VERSION ""

NS_ :

BS_:

BU_:

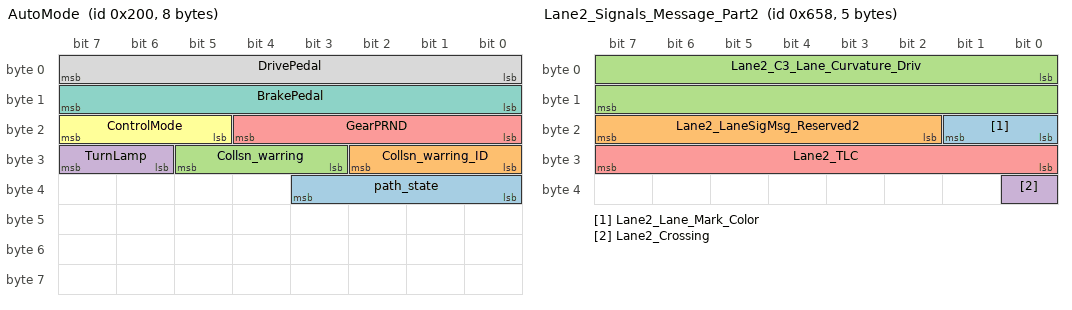
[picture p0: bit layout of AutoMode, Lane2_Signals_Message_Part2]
BO_ 512 AutoMode: 8 Vector__XXX
 SG_ path_state : 35|4@0+ (1,0) [0|15] "" Vector__XXX
 SG_ Collsn_warring_ID : 26|3@0+ (1,0) [0|5] "" Vector__XXX
 SG_ Collsn_warring : 29|3@0+ (1,0) [0|3] "" Vector__XXX
 SG_ TurnLamp : 31|2@0+ (1,0) [0|3] "" Vector__XXX
 SG_ GearPRND : 20|5@0- (1,0) [-9|1] "" Vector__XXX
 SG_ ControlMode : 23|3@0+ (1,0) [0|2] "" Vector__XXX
 SG_ BrakePedal : 15|8@0+ (0.5,0) [0|100] "" Vector__XXX
 SG_ DrivePedal : 7|8@0+ (0.5,0) [0|100] "" Vector__XXX

BO_ 1624 Lane2_Signals_Message_Part2: 5 Vector__XXX
 SG_ Lane2_Lane_Mark_Color : 16|2@1+ (1,0) [0|3] "ENUM" Vector__XXX
 SG_ Lane2_LaneSigMsg_Reserved2 : 18|6@1+ (1,0) [0|0] "NA" Vector__XXX
 SG_ Lane2_C3_Lane_Curvature_Driv : 0|16@1+ (4E-009,-0.000131072) [-0.000131072|0.000131068] "1/m2" Vector__XXX
 SG_ Lane2_Crossing : 32|1@1+ (1,0) [0|1] "bool" Vector__XXX
 SG_ Lane2_TLC : 24|8@1+ (0.01,0) [0|2] "sec" Vector__XXX

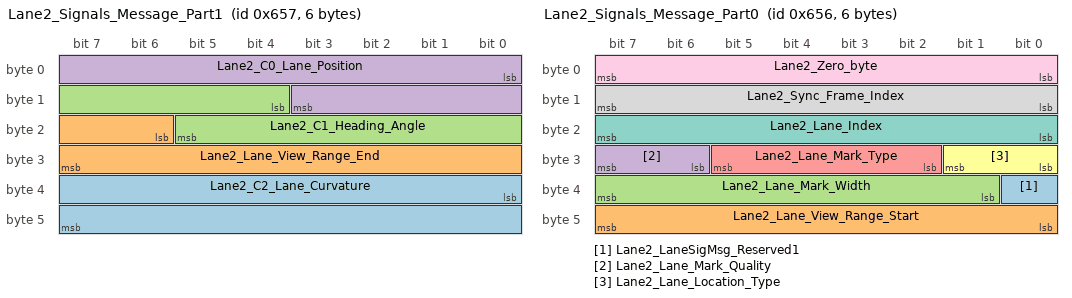
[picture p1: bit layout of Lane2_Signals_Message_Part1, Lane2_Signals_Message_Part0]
BO_ 1623 Lane2_Signals_Message_Part1: 6 Vector__XXX
 SG_ Lane2_C2_Lane_Curvature : 32|16@1+ (1E-006,-0.032768) [-0.032768|0.032767] "1/m" Vector__XXX
 SG_ Lane2_Lane_View_Range_End : 22|10@1+ (0.5,0) [0|150] "m" Vector__XXX
 SG_ Lane2_C1_Heading_Angle : 12|10@1+ (0.0009765625,-0.357) [-0.357|0.357] "rad" Vector__XXX
 SG_ Lane2_C0_Lane_Position : 0|12@1+ (0.01,-20.48) [-20.48|20.47] "m" Vector__XXX

BO_ 1622 Lane2_Signals_Message_Part0: 6 Vector__XXX
 SG_ Lane2_LaneSigMsg_Reserved1 : 32|1@1+ (1,0) [0|0] "NA" Vector__XXX
 SG_ Lane2_Lane_View_Range_Start : 40|8@1+ (0.5,0) [0|63.5] "m" Vector__XXX
 SG_ Lane2_Lane_Mark_Width : 33|7@1+ (0.01,0) [0|0.8] "m" Vector__XXX
 SG_ Lane2_Lane_Mark_Quality : 30|2@1+ (1,0) [0|3] "ENUM" Vector__XXX
 SG_ Lane2_Lane_Mark_Type : 26|4@1+ (1,0) [0|6] "ENUM" Vector__XXX
 SG_ Lane2_Lane_Location_Type : 24|2@1+ (1,0) [0|3] "ENUM" Vector__XXX
 SG_ Lane2_Lane_Index : 16|8@1+ (1,0) [0|3] "counter" Vector__XXX
 SG_ Lane2_Sync_Frame_Index : 8|8@1+ (1,0) [0|255] "counter" Vector__XXX
 SG_ Lane2_Zero_byte : 0|8@1+ (1,0) [0|0] "NA" Vector__XXX

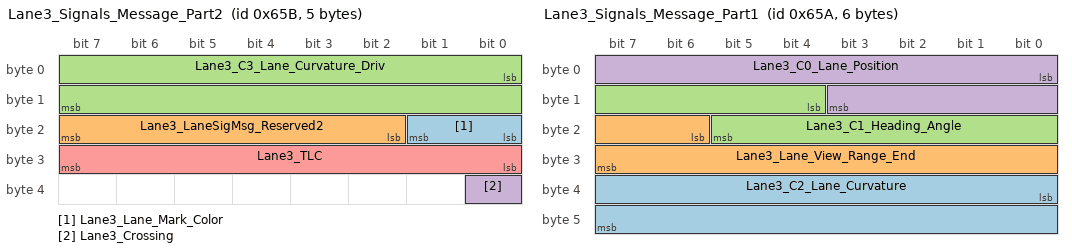
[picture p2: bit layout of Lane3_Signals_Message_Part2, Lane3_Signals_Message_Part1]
BO_ 1627 Lane3_Signals_Message_Part2: 5 Vector__XXX
 SG_ Lane3_Lane_Mark_Color : 16|2@1+ (1,0) [0|3] "ENUM" Vector__XXX
 SG_ Lane3_LaneSigMsg_Reserved2 : 18|6@1+ (1,0) [0|0] "NA" Vector__XXX
 SG_ Lane3_C3_Lane_Curvature_Driv : 0|16@1+ (4E-009,-0.000131072) [-0.000131072|0.000131068] "1/m2" Vector__XXX
 SG_ Lane3_Crossing : 32|1@1+ (1,0) [0|1] "bool" Vector__XXX
 SG_ Lane3_TLC : 24|8@1+ (0.01,0) [0|2] "sec" Vector__XXX

BO_ 1626 Lane3_Signals_Message_Part1: 6 Vector__XXX
 SG_ Lane3_C2_Lane_Curvature : 32|16@1+ (1E-006,-0.032768) [-0.032768|0.032767] "1/m" Vector__XXX
 SG_ Lane3_Lane_View_Range_End : 22|10@1+ (0.5,0) [0|150] "m" Vector__XXX
 SG_ Lane3_C1_Heading_Angle : 12|10@1+ (0.0009765625,-0.357) [-0.357|0.357] "rad" Vector__XXX
 SG_ Lane3_C0_Lane_Position : 0|12@1+ (0.01,-20.48) [-20.48|20.47] "m" Vector__XXX

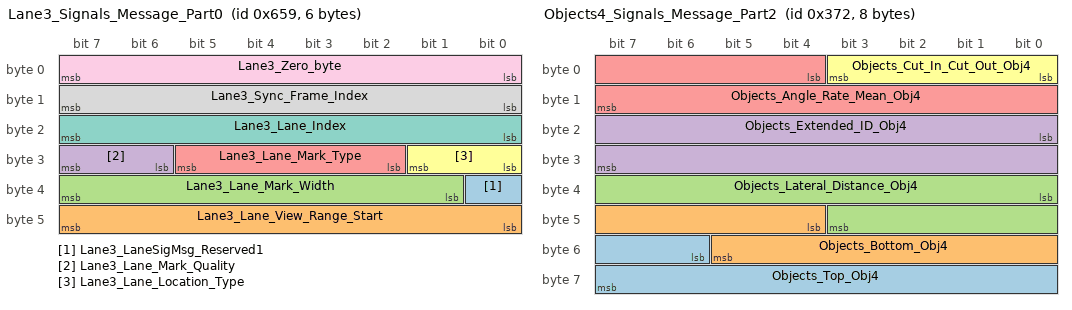
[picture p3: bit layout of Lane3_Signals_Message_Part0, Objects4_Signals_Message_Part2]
BO_ 1625 Lane3_Signals_Message_Part0: 6 Vector__XXX
 SG_ Lane3_LaneSigMsg_Reserved1 : 32|1@1+ (1,0) [0|0] "NA" Vector__XXX
 SG_ Lane3_Lane_View_Range_Start : 40|8@1+ (0.5,0) [0|63.5] "m" Vector__XXX
 SG_ Lane3_Lane_Mark_Width : 33|7@1+ (0.01,0) [0|0.8] "m" Vector__XXX
 SG_ Lane3_Lane_Mark_Quality : 30|2@1+ (1,0) [0|3] "ENUM" Vector__XXX
 SG_ Lane3_Lane_Mark_Type : 26|4@1+ (1,0) [0|6] "ENUM" Vector__XXX
 SG_ Lane3_Lane_Location_Type : 24|2@1+ (1,0) [0|3] "ENUM" Vector__XXX
 SG_ Lane3_Lane_Index : 16|8@1+ (1,0) [0|3] "counter" Vector__XXX
 SG_ Lane3_Sync_Frame_Index : 8|8@1+ (1,0) [0|255] "counter" Vector__XXX
 SG_ Lane3_Zero_byte : 0|8@1+ (1,0) [0|0] "NA" Vector__XXX

BO_ 882 Objects4_Signals_Message_Part2: 8 Vector__XXX
 SG_ Objects_Top_Obj4 : 54|10@1+ (2,-1023) [-1023|1023] "pixels" Vector__XXX
 SG_ Objects_Bottom_Obj4 : 44|10@1+ (2,-1023) [-1023|1023] "pixels" Vector__XXX
 SG_ Objects_Lateral_Distance_Obj4 : 32|12@1+ (0.05,-102.4) [-102.4|102.35] "m" Vector__XXX
 SG_ Objects_Extended_ID_Obj4 : 16|16@1+ (1,0) [0|65535] "counter" Vector__XXX
 SG_ Objects_Angle_Rate_Mean_Obj4 : 4|12@1+ (0.002,-2.234) [-2.234|2.2318] "rad/s" Vector__XXX
 SG_ Objects_Cut_In_Cut_Out_Obj4 : 0|4@1+ (1,0) [0|8] "ENUM" Vector__XXX

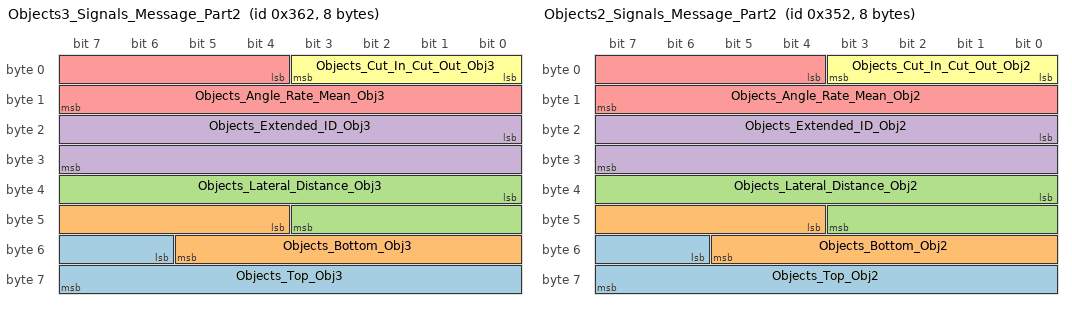
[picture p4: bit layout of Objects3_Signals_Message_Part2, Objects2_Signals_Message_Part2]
BO_ 866 Objects3_Signals_Message_Part2: 8 Vector__XXX
 SG_ Objects_Top_Obj3 : 54|10@1+ (2,-1023) [-1023|1023] "pixels" Vector__XXX
 SG_ Objects_Bottom_Obj3 : 44|10@1+ (2,-1023) [-1023|1023] "pixels" Vector__XXX
 SG_ Objects_Lateral_Distance_Obj3 : 32|12@1+ (0.05,-102.4) [-102.4|102.35] "m" Vector__XXX
 SG_ Objects_Extended_ID_Obj3 : 16|16@1+ (1,0) [0|65535] "counter" Vector__XXX
 SG_ Objects_Angle_Rate_Mean_Obj3 : 4|12@1+ (0.002,-2.234) [-2.234|2.2318] "rad/s" Vector__XXX
 SG_ Objects_Cut_In_Cut_Out_Obj3 : 0|4@1+ (1,0) [0|8] "ENUM" Vector__XXX

BO_ 850 Objects2_Signals_Message_Part2: 8 Vector__XXX
 SG_ Objects_Top_Obj2 : 54|10@1+ (2,-1023) [-1023|1023] "pixels" Vector__XXX
 SG_ Objects_Bottom_Obj2 : 44|10@1+ (2,-1023) [-1023|1023] "pixels" Vector__XXX
 SG_ Objects_Lateral_Distance_Obj2 : 32|12@1+ (0.05,-102.4) [-102.4|102.35] "m" Vector__XXX
 SG_ Objects_Extended_ID_Obj2 : 16|16@1+ (1,0) [0|65535] "counter" Vector__XXX
 SG_ Objects_Angle_Rate_Mean_Obj2 : 4|12@1+ (0.002,-2.234) [-2.234|2.2318] "rad/s" Vector__XXX
 SG_ Objects_Cut_In_Cut_Out_Obj2 : 0|4@1+ (1,0) [0|8] "ENUM" Vector__XXX

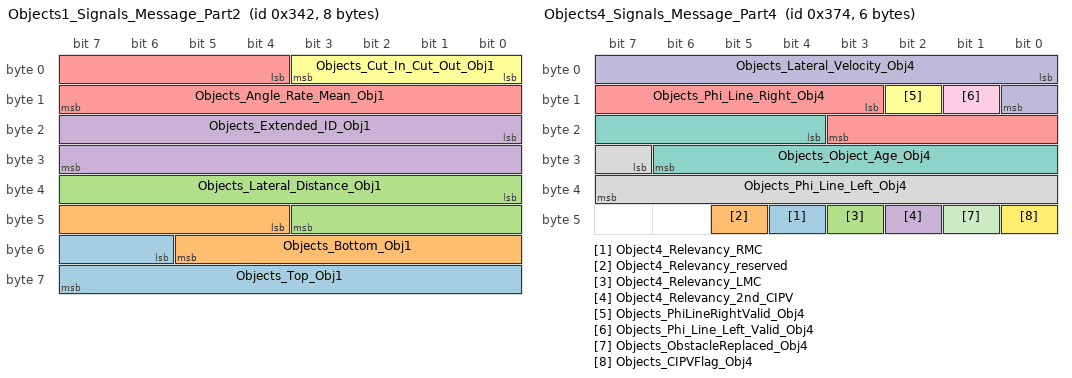
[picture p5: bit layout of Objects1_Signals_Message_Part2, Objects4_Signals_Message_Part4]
BO_ 834 Objects1_Signals_Message_Part2: 8 Vector__XXX
 SG_ Objects_Top_Obj1 : 54|10@1+ (2,-1023) [-1023|1023] "pixels" Vector__XXX
 SG_ Objects_Bottom_Obj1 : 44|10@1+ (2,-1023) [-1023|1023] "pixels" Vector__XXX
 SG_ Objects_Lateral_Distance_Obj1 : 32|12@1+ (0.05,-102.4) [-102.4|102.35] "m" Vector__XXX
 SG_ Objects_Extended_ID_Obj1 : 16|16@1+ (1,0) [0|65535] "counter" Vector__XXX
 SG_ Objects_Angle_Rate_Mean_Obj1 : 4|12@1+ (0.002,-2.234) [-2.234|2.2318] "rad/s" Vector__XXX
 SG_ Objects_Cut_In_Cut_Out_Obj1 : 0|4@1+ (1,0) [0|8] "ENUM" Vector__XXX

BO_ 884 Objects4_Signals_Message_Part4: 6 Vector__XXX
 SG_ Object4_Relevancy_RMC : 44|1@1+ (1,0) [0|0] "boot" Vector__XXX
 SG_ Object4_Relevancy_reserved : 45|1@1+ (1,0) [0|0] "bool" Vector__XXX
 SG_ Object4_Relevancy_LMC : 43|1@1+ (1,0) [0|0] "bool" Vector__XXX
 SG_ Object4_Relevancy_2nd_CIPV : 42|1@1+ (1,0) [0|0] "bool" Vector__XXX
 SG_ Objects_Phi_Line_Right_Obj4 : 11|9@1+ (0.0010246551382,-0.2617993878) [-0.2617993878|0.2617993878] "rad" Vector__XXX
 SG_ Objects_PhiLineRightValid_Obj4 : 10|1@1+ (1,0) [0|1] "bool" Vector__XXX
 SG_ Objects_Object_Age_Obj4 : 20|11@1+ (1,0) [0|2047] "frames" Vector__XXX
 SG_ Objects_Phi_Line_Left_Obj4 : 31|9@1+ (0.0010246551382,-0.2617993878) [-0.2617993878|0.2617993878] "rad" Vector__XXX
 SG_ Objects_Phi_Line_Left_Valid_Obj4 : 9|1@1+ (1,0) [0|1] "bool" Vector__XXX
 SG_ Objects_Lateral_Velocity_Obj4 : 0|9@1+ (0.05,-12.8) [-12.8|12.75] "m/s" Vector__XXX
 SG_ Objects_ObstacleReplaced_Obj4 : 41|1@1+ (1,0) [0|1] "bool" Vector__XXX
 SG_ Objects_CIPVFlag_Obj4 : 40|1@1+ (1,0) [0|1] "bool" Vector__XXX

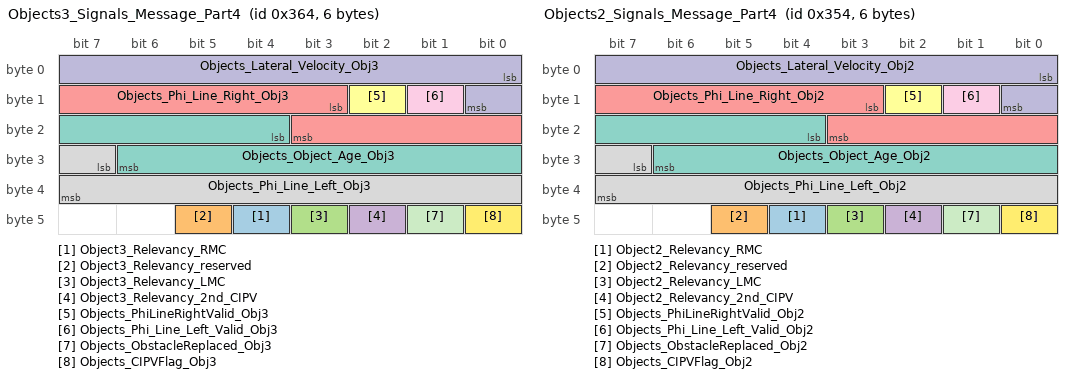
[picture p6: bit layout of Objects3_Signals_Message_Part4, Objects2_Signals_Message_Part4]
BO_ 868 Objects3_Signals_Message_Part4: 6 Vector__XXX
 SG_ Object3_Relevancy_RMC : 44|1@1+ (1,0) [0|0] "boot" Vector__XXX
 SG_ Object3_Relevancy_reserved : 45|1@1+ (1,0) [0|0] "bool" Vector__XXX
 SG_ Object3_Relevancy_LMC : 43|1@1+ (1,0) [0|0] "bool" Vector__XXX
 SG_ Object3_Relevancy_2nd_CIPV : 42|1@1+ (1,0) [0|0] "bool" Vector__XXX
 SG_ Objects_Phi_Line_Right_Obj3 : 11|9@1+ (0.0010246551382,-0.2617993878) [-0.2617993878|0.2617993878] "rad" Vector__XXX
 SG_ Objects_PhiLineRightValid_Obj3 : 10|1@1+ (1,0) [0|1] "bool" Vector__XXX
 SG_ Objects_Object_Age_Obj3 : 20|11@1+ (1,0) [0|2047] "frames" Vector__XXX
 SG_ Objects_Phi_Line_Left_Obj3 : 31|9@1+ (0.0010246551382,-0.2617993878) [-0.2617993878|0.2617993878] "rad" Vector__XXX
 SG_ Objects_Phi_Line_Left_Valid_Obj3 : 9|1@1+ (1,0) [0|1] "bool" Vector__XXX
 SG_ Objects_Lateral_Velocity_Obj3 : 0|9@1+ (0.05,-12.8) [-12.8|12.75] "m/s" Vector__XXX
 SG_ Objects_ObstacleReplaced_Obj3 : 41|1@1+ (1,0) [0|1] "bool" Vector__XXX
 SG_ Objects_CIPVFlag_Obj3 : 40|1@1+ (1,0) [0|1] "bool" Vector__XXX

BO_ 852 Objects2_Signals_Message_Part4: 6 Vector__XXX
 SG_ Object2_Relevancy_RMC : 44|1@1+ (1,0) [0|0] "boot" Vector__XXX
 SG_ Object2_Relevancy_reserved : 45|1@1+ (1,0) [0|0] "bool" Vector__XXX
 SG_ Object2_Relevancy_LMC : 43|1@1+ (1,0) [0|0] "bool" Vector__XXX
 SG_ Object2_Relevancy_2nd_CIPV : 42|1@1+ (1,0) [0|0] "bool" Vector__XXX
 SG_ Objects_Phi_Line_Right_Obj2 : 11|9@1+ (0.0010246551382,-0.2617993878) [-0.2617993878|0.2617993878] "rad" Vector__XXX
 SG_ Objects_PhiLineRightValid_Obj2 : 10|1@1+ (1,0) [0|1] "bool" Vector__XXX
 SG_ Objects_Object_Age_Obj2 : 20|11@1+ (1,0) [0|2047] "frames" Vector__XXX
 SG_ Objects_Phi_Line_Left_Obj2 : 31|9@1+ (0.0010246551382,-0.2617993878) [-0.2617993878|0.2617993878] "rad" Vector__XXX
 SG_ Objects_Phi_Line_Left_Valid_Obj2 : 9|1@1+ (1,0) [0|1] "bool" Vector__XXX
 SG_ Objects_Lateral_Velocity_Obj2 : 0|9@1+ (0.05,-12.8) [-12.8|12.75] "m/s" Vector__XXX
 SG_ Objects_ObstacleReplaced_Obj2 : 41|1@1+ (1,0) [0|1] "bool" Vector__XXX
 SG_ Objects_CIPVFlag_Obj2 : 40|1@1+ (1,0) [0|1] "bool" Vector__XXX

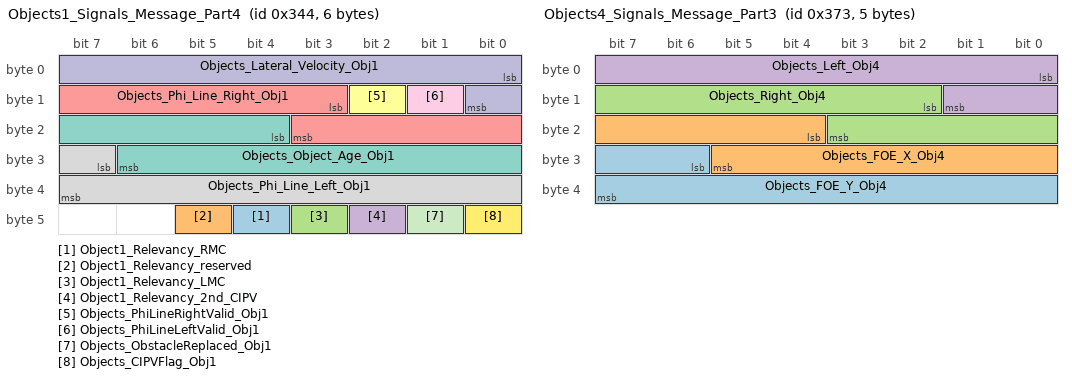
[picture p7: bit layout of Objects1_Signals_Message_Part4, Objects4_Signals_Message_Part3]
BO_ 836 Objects1_Signals_Message_Part4: 6 Vector__XXX
 SG_ Object1_Relevancy_RMC : 44|1@1+ (1,0) [0|0] "boot" Vector__XXX
 SG_ Object1_Relevancy_reserved : 45|1@1+ (1,0) [0|0] "bool" Vector__XXX
 SG_ Object1_Relevancy_LMC : 43|1@1+ (1,0) [0|0] "bool" Vector__XXX
 SG_ Object1_Relevancy_2nd_CIPV : 42|1@1+ (1,0) [0|0] "bool" Vector__XXX
 SG_ Objects_Phi_Line_Right_Obj1 : 11|9@1+ (0.0010246551382,-0.2617993878) [-0.2617993878|0.2617993878] "rad" Vector__XXX
 SG_ Objects_PhiLineRightValid_Obj1 : 10|1@1+ (1,0) [0|1] "bool" Vector__XXX
 SG_ Objects_Object_Age_Obj1 : 20|11@1+ (1,0) [0|2047] "frames" Vector__XXX
 SG_ Objects_Phi_Line_Left_Obj1 : 31|9@1+ (0.0010246551382,-0.2617993878) [-0.2617993878|0.2617993878] "rad" Vector__XXX
 SG_ Objects_PhiLineLeftValid_Obj1 : 9|1@1+ (1,0) [0|1] "bool" Vector__XXX
 SG_ Objects_Lateral_Velocity_Obj1 : 0|9@1+ (0.05,-12.8) [-12.8|12.75] "m/s" Vector__XXX
 SG_ Objects_ObstacleReplaced_Obj1 : 41|1@1+ (1,0) [0|1] "bool" Vector__XXX
 SG_ Objects_CIPVFlag_Obj1 : 40|1@1+ (1,0) [0|1] "bool" Vector__XXX

BO_ 883 Objects4_Signals_Message_Part3: 5 Vector__XXX
 SG_ Objects_FOE_Y_Obj4 : 30|10@1+ (2,-1023) [-1023|1023] "pixels" Vector__XXX
 SG_ Objects_FOE_X_Obj4 : 20|10@1+ (2,-1023) [-1023|1023] "pixels" Vector__XXX
 SG_ Objects_Right_Obj4 : 10|10@1+ (2,-1023) [-1023|1023] "pixels" Vector__XXX
 SG_ Objects_Left_Obj4 : 0|10@1+ (2,-1023) [-1023|1023] "pixels" Vector__XXX

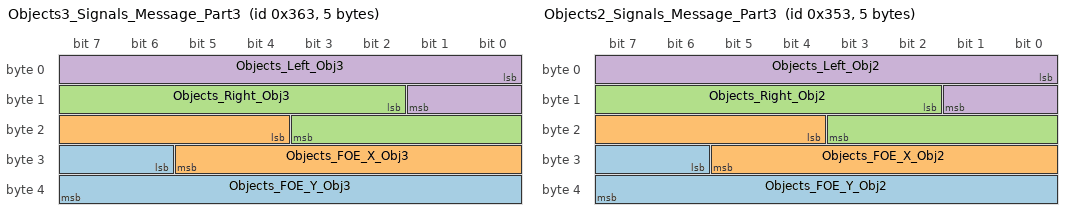
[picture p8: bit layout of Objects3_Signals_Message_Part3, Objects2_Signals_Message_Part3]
BO_ 867 Objects3_Signals_Message_Part3: 5 Vector__XXX
 SG_ Objects_FOE_Y_Obj3 : 30|10@1+ (2,-1023) [-1023|1023] "pixels" Vector__XXX
 SG_ Objects_FOE_X_Obj3 : 20|10@1+ (2,-1023) [-1023|1023] "pixels" Vector__XXX
 SG_ Objects_Right_Obj3 : 10|10@1+ (2,-1023) [-1023|1023] "pixels" Vector__XXX
 SG_ Objects_Left_Obj3 : 0|10@1+ (2,-1023) [-1023|1023] "pixels" Vector__XXX

BO_ 851 Objects2_Signals_Message_Part3: 5 Vector__XXX
 SG_ Objects_FOE_Y_Obj2 : 30|10@1+ (2,-1023) [-1023|1023] "pixels" Vector__XXX
 SG_ Objects_FOE_X_Obj2 : 20|10@1+ (2,-1023) [-1023|1023] "pixels" Vector__XXX
 SG_ Objects_Right_Obj2 : 10|10@1+ (2,-1023) [-1023|1023] "pixels" Vector__XXX
 SG_ Objects_Left_Obj2 : 0|10@1+ (2,-1023) [-1023|1023] "pixels" Vector__XXX

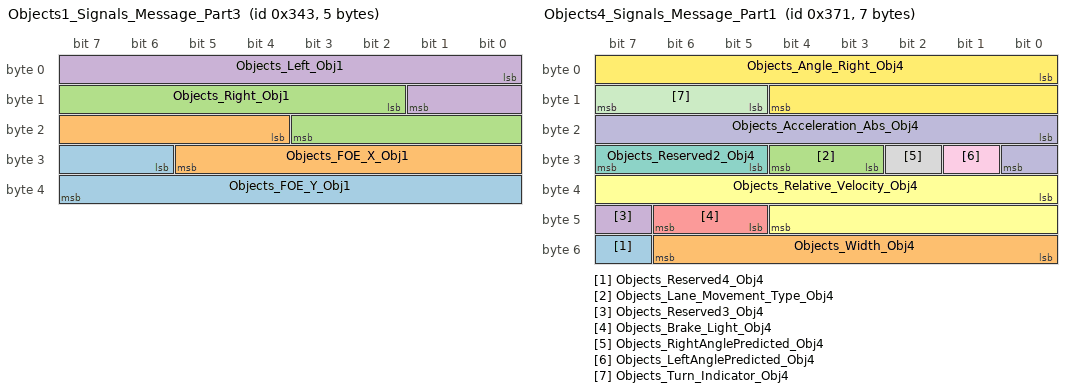
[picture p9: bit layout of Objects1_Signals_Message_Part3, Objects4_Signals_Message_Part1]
BO_ 835 Objects1_Signals_Message_Part3: 5 Vector__XXX
 SG_ Objects_FOE_Y_Obj1 : 30|10@1+ (2,-1023) [-1023|1023] "pixels" Vector__XXX
 SG_ Objects_FOE_X_Obj1 : 20|10@1+ (2,-1023) [-1023|1023] "pixels" Vector__XXX
 SG_ Objects_Right_Obj1 : 10|10@1+ (2,-1023) [-1023|1023] "pixels" Vector__XXX
 SG_ Objects_Left_Obj1 : 0|10@1+ (2,-1023) [-1023|1023] "pixels" Vector__XXX

BO_ 881 Objects4_Signals_Message_Part1: 7 Vector__XXX
 SG_ Objects_Reserved4_Obj4 : 55|1@1+ (1,0) [0|0] "NA" Vector__XXX
 SG_ Objects_Width_Obj4 : 48|7@1+ (0.05,0) [0|6.35] "m" Vector__XXX
 SG_ Objects_Lane_Movement_Type_Obj4 : 27|2@1+ (1,0) [0|2] "ENUM" Vector__XXX
 SG_ Objects_Reserved3_Obj4 : 47|1@1+ (1,0) [0|0] "NA" Vector__XXX
 SG_ Objects_Brake_Light_Obj4 : 45|2@1+ (1,0) [0|2] "ENUM" Vector__XXX
 SG_ Objects_Relative_Velocity_Obj4 : 32|13@1+ (0.05,-128) [-128|128] "m/s" Vector__XXX
 SG_ Objects_Reserved2_Obj4 : 29|3@1+ (1,0) [0|0] "NA" Vector__XXX
 SG_ Objects_RightAnglePredicted_Obj4 : 26|1@1+ (1,0) [0|1] "bool" Vector__XXX
 SG_ Objects_LeftAnglePredicted_Obj4 : 25|1@1+ (1,0) [0|1] "bool" Vector__XXX
 SG_ Objects_Acceleration_Abs_Obj4 : 16|9@1+ (0.05,-12.8) [-12.8|12.75] "m/s2" Vector__XXX
 SG_ Objects_Turn_Indicator_Obj4 : 13|3@1+ (1,0) [0|4] "ENUM" Vector__XXX
 SG_ Objects_Angle_Right_Obj4 : 0|13@1+ (0.0002,-0.8192) [-0.8192|0.819] "rad" Vector__XXX

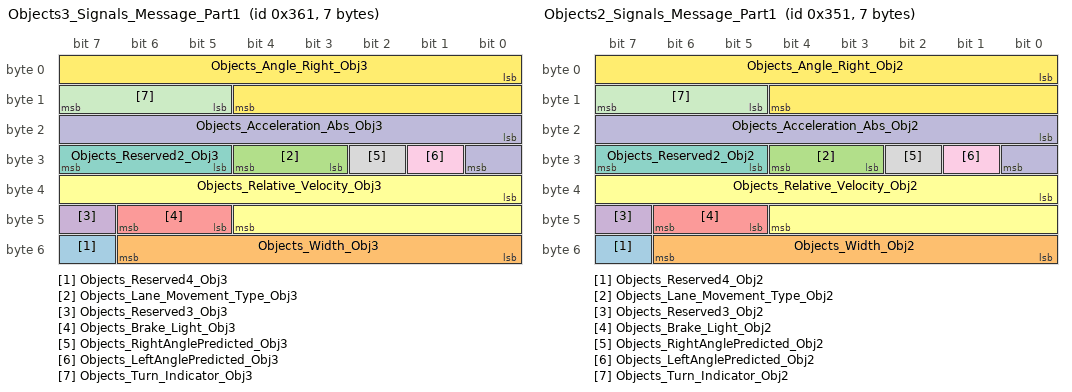
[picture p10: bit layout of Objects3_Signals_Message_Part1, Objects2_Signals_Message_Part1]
BO_ 865 Objects3_Signals_Message_Part1: 7 Vector__XXX
 SG_ Objects_Reserved4_Obj3 : 55|1@1+ (1,0) [0|0] "NA" Vector__XXX
 SG_ Objects_Width_Obj3 : 48|7@1+ (0.05,0) [0|6.35] "m" Vector__XXX
 SG_ Objects_Lane_Movement_Type_Obj3 : 27|2@1+ (1,0) [0|2] "ENUM" Vector__XXX
 SG_ Objects_Reserved3_Obj3 : 47|1@1+ (1,0) [0|0] "NA" Vector__XXX
 SG_ Objects_Brake_Light_Obj3 : 45|2@1+ (1,0) [0|2] "ENUM" Vector__XXX
 SG_ Objects_Relative_Velocity_Obj3 : 32|13@1+ (0.05,-128) [-128|128] "m/s" Vector__XXX
 SG_ Objects_Reserved2_Obj3 : 29|3@1+ (1,0) [0|0] "NA" Vector__XXX
 SG_ Objects_RightAnglePredicted_Obj3 : 26|1@1+ (1,0) [0|1] "bool" Vector__XXX
 SG_ Objects_LeftAnglePredicted_Obj3 : 25|1@1+ (1,0) [0|1] "bool" Vector__XXX
 SG_ Objects_Acceleration_Abs_Obj3 : 16|9@1+ (0.05,-12.8) [-12.8|12.75] "m/s2" Vector__XXX
 SG_ Objects_Turn_Indicator_Obj3 : 13|3@1+ (1,0) [0|4] "ENUM" Vector__XXX
 SG_ Objects_Angle_Right_Obj3 : 0|13@1+ (0.0002,-0.8192) [-0.8192|0.819] "rad" Vector__XXX

BO_ 849 Objects2_Signals_Message_Part1: 7 Vector__XXX
 SG_ Objects_Reserved4_Obj2 : 55|1@1+ (1,0) [0|0] "NA" Vector__XXX
 SG_ Objects_Width_Obj2 : 48|7@1+ (0.05,0) [0|6.35] "m" Vector__XXX
 SG_ Objects_Lane_Movement_Type_Obj2 : 27|2@1+ (1,0) [0|2] "ENUM" Vector__XXX
 SG_ Objects_Reserved3_Obj2 : 47|1@1+ (1,0) [0|0] "NA" Vector__XXX
 SG_ Objects_Brake_Light_Obj2 : 45|2@1+ (1,0) [0|2] "ENUM" Vector__XXX
 SG_ Objects_Relative_Velocity_Obj2 : 32|13@1+ (0.05,-128) [-128|128] "m/s" Vector__XXX
 SG_ Objects_Reserved2_Obj2 : 29|3@1+ (1,0) [0|0] "NA" Vector__XXX
 SG_ Objects_RightAnglePredicted_Obj2 : 26|1@1+ (1,0) [0|1] "bool" Vector__XXX
 SG_ Objects_LeftAnglePredicted_Obj2 : 25|1@1+ (1,0) [0|1] "bool" Vector__XXX
 SG_ Objects_Acceleration_Abs_Obj2 : 16|9@1+ (0.05,-12.8) [-12.8|12.75] "m/s2" Vector__XXX
 SG_ Objects_Turn_Indicator_Obj2 : 13|3@1+ (1,0) [0|4] "ENUM" Vector__XXX
 SG_ Objects_Angle_Right_Obj2 : 0|13@1+ (0.0002,-0.8192) [-0.8192|0.819] "rad" Vector__XXX

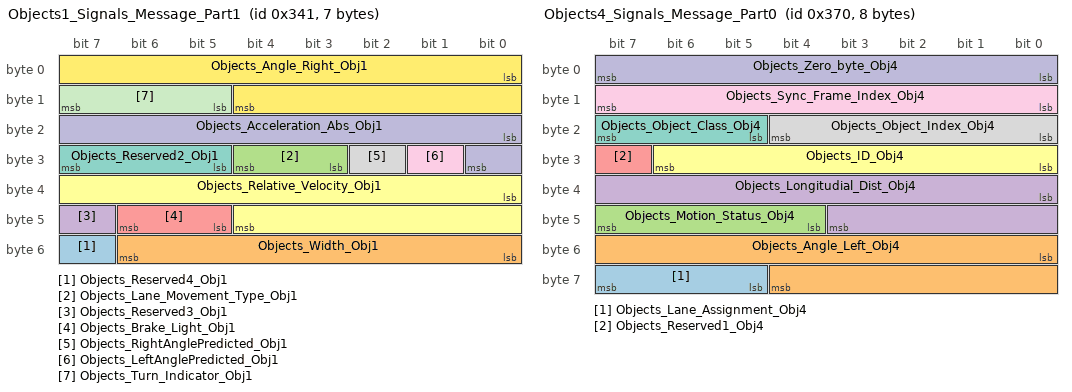
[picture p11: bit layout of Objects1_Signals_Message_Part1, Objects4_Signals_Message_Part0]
BO_ 833 Objects1_Signals_Message_Part1: 7 Vector__XXX
 SG_ Objects_Reserved4_Obj1 : 55|1@1+ (1,0) [0|0] "NA" Vector__XXX
 SG_ Objects_Width_Obj1 : 48|7@1+ (0.05,0) [0|6.35] "m" Vector__XXX
 SG_ Objects_Lane_Movement_Type_Obj1 : 27|2@1+ (1,0) [0|2] "ENUM" Vector__XXX
 SG_ Objects_Reserved3_Obj1 : 47|1@1+ (1,0) [0|0] "NA" Vector__XXX
 SG_ Objects_Brake_Light_Obj1 : 45|2@1+ (1,0) [0|2] "ENUM" Vector__XXX
 SG_ Objects_Relative_Velocity_Obj1 : 32|13@1+ (0.05,-128) [-128|128] "m/s" Vector__XXX
 SG_ Objects_Reserved2_Obj1 : 29|3@1+ (1,0) [0|0] "NA" Vector__XXX
 SG_ Objects_RightAnglePredicted_Obj1 : 26|1@1+ (1,0) [0|1] "bool" Vector__XXX
 SG_ Objects_LeftAnglePredicted_Obj1 : 25|1@1+ (1,0) [0|1] "bool" Vector__XXX
 SG_ Objects_Acceleration_Abs_Obj1 : 16|9@1+ (0.05,-12.8) [-12.8|12.75] "m/s2" Vector__XXX
 SG_ Objects_Turn_Indicator_Obj1 : 13|3@1+ (1,0) [0|4] "ENUM" Vector__XXX
 SG_ Objects_Angle_Right_Obj1 : 0|13@1+ (0.0002,-0.8192) [-0.8192|0.819] "rad" Vector__XXX

BO_ 880 Objects4_Signals_Message_Part0: 8 Vector__XXX
 SG_ Objects_Lane_Assignment_Obj4 : 61|3@1+ (1,0) [0|5] "ENUM" Vector__XXX
 SG_ Objects_Angle_Left_Obj4 : 48|13@1+ (0.0002,-0.8192) [-0.8192|0.819] "rad" Vector__XXX
 SG_ Objects_Motion_Status_Obj4 : 44|4@1+ (1,0) [0|8] "ENUM" Vector__XXX
 SG_ Objects_Longitudial_Dist_Obj4 : 32|12@1+ (0.05,0) [0|204.75] "m" Vector__XXX
 SG_ Objects_Reserved1_Obj4 : 31|1@1+ (1,0) [0|0] "NA" Vector__XXX
 SG_ Objects_ID_Obj4 : 24|7@1+ (1,0) [1|63] "counter" Vector__XXX
 SG_ Objects_Object_Class_Obj4 : 21|3@1+ (1,0) [0|6] "ENUM" Vector__XXX
 SG_ Objects_Object_Index_Obj4 : 16|5@1+ (1,0) [0|19] "counter" Vector__XXX
 SG_ Objects_Sync_Frame_Index_Obj4 : 8|8@1+ (1,0) [0|255] "counter" Vector__XXX
 SG_ Objects_Zero_byte_Obj4 : 0|8@1+ (1,0) [0|0] "NA" Vector__XXX

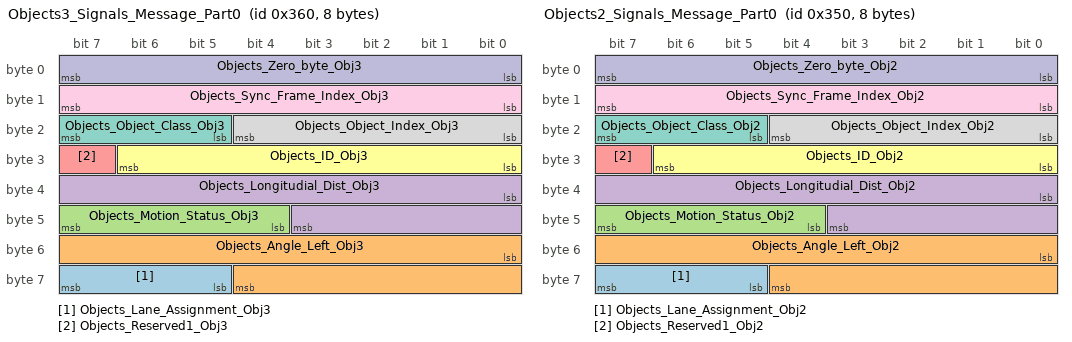
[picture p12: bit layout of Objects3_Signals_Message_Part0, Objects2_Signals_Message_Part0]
BO_ 864 Objects3_Signals_Message_Part0: 8 Vector__XXX
 SG_ Objects_Lane_Assignment_Obj3 : 61|3@1+ (1,0) [0|5] "ENUM" Vector__XXX
 SG_ Objects_Angle_Left_Obj3 : 48|13@1+ (0.0002,-0.8192) [-0.8192|0.819] "rad" Vector__XXX
 SG_ Objects_Motion_Status_Obj3 : 44|4@1+ (1,0) [0|8] "ENUM" Vector__XXX
 SG_ Objects_Longitudial_Dist_Obj3 : 32|12@1+ (0.05,0) [0|204.75] "m" Vector__XXX
 SG_ Objects_Reserved1_Obj3 : 31|1@1+ (1,0) [0|0] "NA" Vector__XXX
 SG_ Objects_ID_Obj3 : 24|7@1+ (1,0) [1|63] "counter" Vector__XXX
 SG_ Objects_Object_Class_Obj3 : 21|3@1+ (1,0) [0|6] "ENUM" Vector__XXX
 SG_ Objects_Object_Index_Obj3 : 16|5@1+ (1,0) [0|19] "counter" Vector__XXX
 SG_ Objects_Sync_Frame_Index_Obj3 : 8|8@1+ (1,0) [0|255] "counter" Vector__XXX
 SG_ Objects_Zero_byte_Obj3 : 0|8@1+ (1,0) [0|0] "NA" Vector__XXX

BO_ 848 Objects2_Signals_Message_Part0: 8 Vector__XXX
 SG_ Objects_Lane_Assignment_Obj2 : 61|3@1+ (1,0) [0|5] "ENUM" Vector__XXX
 SG_ Objects_Angle_Left_Obj2 : 48|13@1+ (0.0002,-0.8192) [-0.8192|0.819] "rad" Vector__XXX
 SG_ Objects_Motion_Status_Obj2 : 44|4@1+ (1,0) [0|8] "ENUM" Vector__XXX
 SG_ Objects_Longitudial_Dist_Obj2 : 32|12@1+ (0.05,0) [0|204.75] "m" Vector__XXX
 SG_ Objects_Reserved1_Obj2 : 31|1@1+ (1,0) [0|0] "NA" Vector__XXX
 SG_ Objects_ID_Obj2 : 24|7@1+ (1,0) [1|63] "counter" Vector__XXX
 SG_ Objects_Object_Class_Obj2 : 21|3@1+ (1,0) [0|6] "ENUM" Vector__XXX
 SG_ Objects_Object_Index_Obj2 : 16|5@1+ (1,0) [0|19] "counter" Vector__XXX
 SG_ Objects_Sync_Frame_Index_Obj2 : 8|8@1+ (1,0) [0|255] "counter" Vector__XXX
 SG_ Objects_Zero_byte_Obj2 : 0|8@1+ (1,0) [0|0] "NA" Vector__XXX

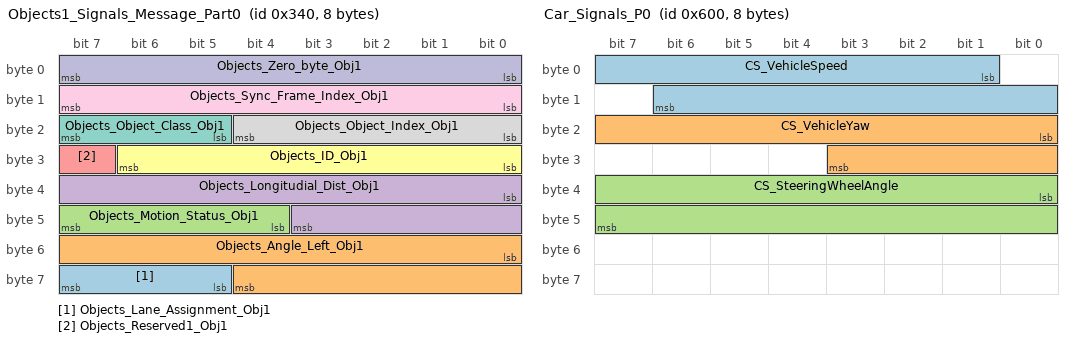
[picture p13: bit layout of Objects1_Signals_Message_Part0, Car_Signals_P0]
BO_ 832 Objects1_Signals_Message_Part0: 8 Vector__XXX
 SG_ Objects_Lane_Assignment_Obj1 : 61|3@1+ (1,0) [0|5] "ENUM" Vector__XXX
 SG_ Objects_Angle_Left_Obj1 : 48|13@1+ (0.0002,-0.8192) [-0.8192|0.819] "rad" Vector__XXX
 SG_ Objects_Motion_Status_Obj1 : 44|4@1+ (1,0) [0|8] "ENUM" Vector__XXX
 SG_ Objects_Longitudial_Dist_Obj1 : 32|12@1+ (0.05,0) [0|204.75] "m" Vector__XXX
 SG_ Objects_Reserved1_Obj1 : 31|1@1+ (1,0) [0|0] "NA" Vector__XXX
 SG_ Objects_ID_Obj1 : 24|7@1+ (1,0) [1|63] "counter" Vector__XXX
 SG_ Objects_Object_Class_Obj1 : 21|3@1+ (1,0) [0|6] "ENUM" Vector__XXX
 SG_ Objects_Object_Index_Obj1 : 16|5@1+ (1,0) [0|19] "counter" Vector__XXX
 SG_ Objects_Sync_Frame_Index_Obj1 : 8|8@1+ (1,0) [0|255] "counter" Vector__XXX
 SG_ Objects_Zero_byte_Obj1 : 0|8@1+ (1,0) [0|0] "NA" Vector__XXX

BO_ 1536 Car_Signals_P0: 8 Vector__XXX
 SG_ CS_VehicleSpeed : 1|14@1+ (0.01,0) [0|163.83] "m/s" Vector__XXX
 SG_ CS_VehicleYaw : 16|12@1+ (0.0625,-128) [-128|127.938] "deg/sec" Vector__XXX
 SG_ CS_SteeringWheelAngle : 32|16@1+ (0.0625,-2048) [-2048|2047.94] "deg" Vector__XXX

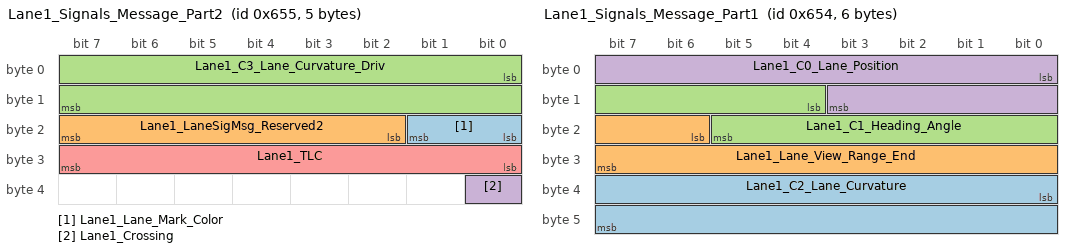
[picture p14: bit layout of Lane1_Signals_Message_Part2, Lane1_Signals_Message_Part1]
BO_ 1621 Lane1_Signals_Message_Part2: 5 Vector__XXX
 SG_ Lane1_Lane_Mark_Color : 16|2@1+ (1,0) [0|3] "ENUM" Vector__XXX
 SG_ Lane1_LaneSigMsg_Reserved2 : 18|6@1+ (1,0) [0|0] "NA" Vector__XXX
 SG_ Lane1_C3_Lane_Curvature_Driv : 0|16@1+ (4E-009,-0.000131072) [-0.000131072|0.000131068] "1/m2" Vector__XXX
 SG_ Lane1_Crossing : 32|1@1+ (1,0) [0|1] "bool" Vector__XXX
 SG_ Lane1_TLC : 24|8@1+ (0.01,0) [0|2] "sec" Vector__XXX

BO_ 1620 Lane1_Signals_Message_Part1: 6 Vector__XXX
 SG_ Lane1_C2_Lane_Curvature : 32|16@1+ (1E-006,-0.032768) [-0.032768|0.032767] "1/m" Vector__XXX
 SG_ Lane1_Lane_View_Range_End : 22|10@1+ (0.5,0) [0|150] "m" Vector__XXX
 SG_ Lane1_C1_Heading_Angle : 12|10@1+ (0.0009765625,-0.357) [-0.357|0.357] "rad" Vector__XXX
 SG_ Lane1_C0_Lane_Position : 0|12@1+ (0.01,-20.48) [-20.48|20.47] "m" Vector__XXX

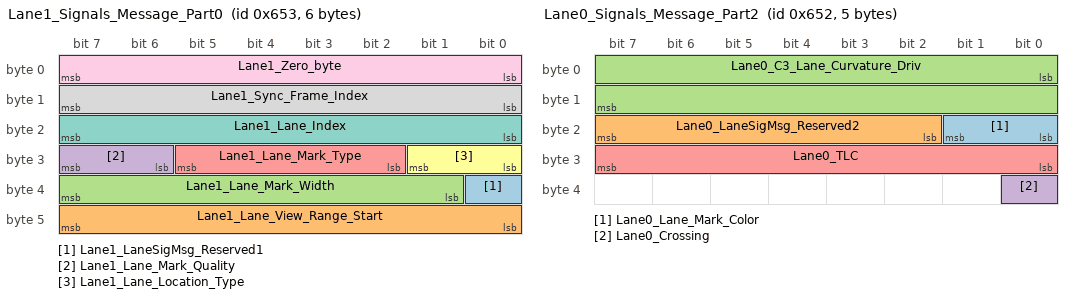
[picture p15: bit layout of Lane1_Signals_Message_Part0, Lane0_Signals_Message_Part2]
BO_ 1619 Lane1_Signals_Message_Part0: 6 Vector__XXX
 SG_ Lane1_LaneSigMsg_Reserved1 : 32|1@1+ (1,0) [0|0] "NA" Vector__XXX
 SG_ Lane1_Lane_View_Range_Start : 40|8@1+ (0.5,0) [0|63.5] "m" Vector__XXX
 SG_ Lane1_Lane_Mark_Width : 33|7@1+ (0.01,0) [0|0.8] "m" Vector__XXX
 SG_ Lane1_Lane_Mark_Quality : 30|2@1+ (1,0) [0|3] "ENUM" Vector__XXX
 SG_ Lane1_Lane_Mark_Type : 26|4@1+ (1,0) [0|6] "ENUM" Vector__XXX
 SG_ Lane1_Lane_Location_Type : 24|2@1+ (1,0) [0|3] "ENUM" Vector__XXX
 SG_ Lane1_Lane_Index : 16|8@1+ (1,0) [0|3] "counter" Vector__XXX
 SG_ Lane1_Sync_Frame_Index : 8|8@1+ (1,0) [0|255] "counter" Vector__XXX
 SG_ Lane1_Zero_byte : 0|8@1+ (1,0) [0|0] "NA" Vector__XXX

BO_ 1618 Lane0_Signals_Message_Part2: 5 Vector__XXX
 SG_ Lane0_Lane_Mark_Color : 16|2@1+ (1,0) [0|3] "ENUM" Vector__XXX
 SG_ Lane0_LaneSigMsg_Reserved2 : 18|6@1+ (1,0) [0|0] "NA" Vector__XXX
 SG_ Lane0_C3_Lane_Curvature_Driv : 0|16@1+ (4E-009,-0.000131072) [-0.000131072|0.000131068] "1/m2" Vector__XXX
 SG_ Lane0_Crossing : 32|1@1+ (1,0) [0|1] "bool" Vector__XXX
 SG_ Lane0_TLC : 24|8@1+ (0.01,0) [0|2] "sec" Vector__XXX

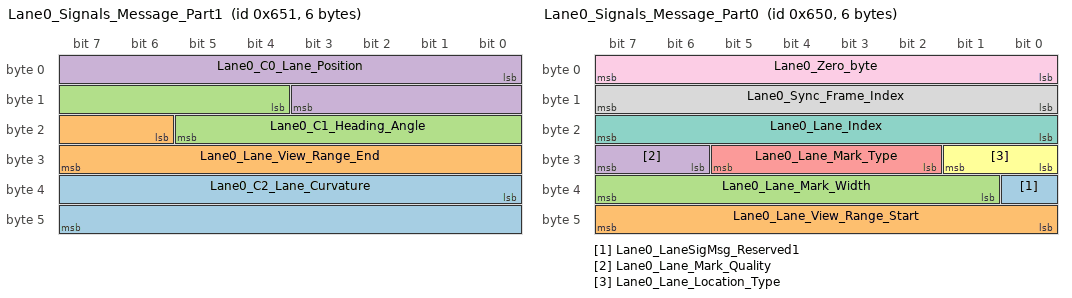
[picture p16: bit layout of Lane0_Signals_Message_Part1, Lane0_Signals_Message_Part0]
BO_ 1617 Lane0_Signals_Message_Part1: 6 Vector__XXX
 SG_ Lane0_C2_Lane_Curvature : 32|16@1+ (1E-006,-0.032768) [-0.032768|0.032767] "1/m" Vector__XXX
 SG_ Lane0_Lane_View_Range_End : 22|10@1+ (0.5,0) [0|150] "m" Vector__XXX
 SG_ Lane0_C1_Heading_Angle : 12|10@1+ (0.0009765625,-0.357) [-0.357|0.357] "rad" Vector__XXX
 SG_ Lane0_C0_Lane_Position : 0|12@1+ (0.01,-20.48) [-20.48|20.47] "m" Vector__XXX

BO_ 1616 Lane0_Signals_Message_Part0: 6 Vector__XXX
 SG_ Lane0_LaneSigMsg_Reserved1 : 32|1@1+ (1,0) [0|0] "NA" Vector__XXX
 SG_ Lane0_Lane_View_Range_Start : 40|8@1+ (0.5,0) [0|63.5] "m" Vector__XXX
 SG_ Lane0_Lane_Mark_Width : 33|7@1+ (0.01,0) [0|0.8] "m" Vector__XXX
 SG_ Lane0_Lane_Mark_Quality : 30|2@1+ (1,0) [0|3] "ENUM" Vector__XXX
 SG_ Lane0_Lane_Mark_Type : 26|4@1+ (1,0) [0|6] "ENUM" Vector__XXX
 SG_ Lane0_Lane_Location_Type : 24|2@1+ (1,0) [0|3] "ENUM" Vector__XXX
 SG_ Lane0_Lane_Index : 16|8@1+ (1,0) [0|3] "counter" Vector__XXX
 SG_ Lane0_Sync_Frame_Index : 8|8@1+ (1,0) [0|255] "counter" Vector__XXX
 SG_ Lane0_Zero_byte : 0|8@1+ (1,0) [0|0] "NA" Vector__XXX

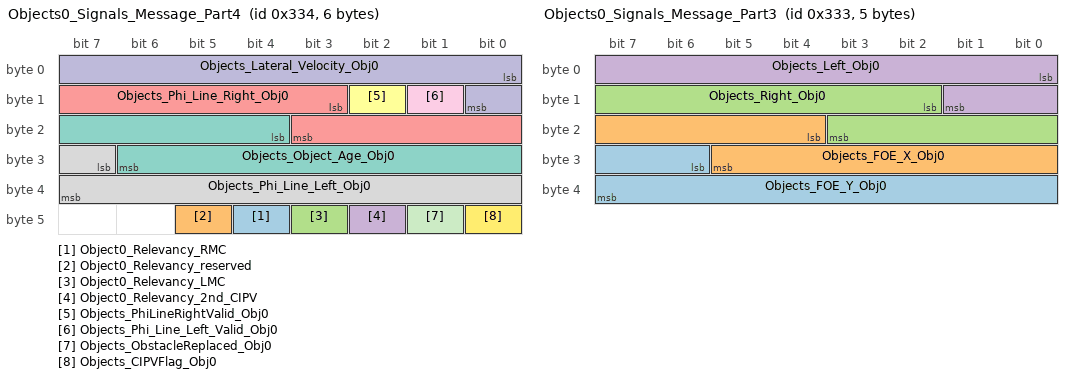
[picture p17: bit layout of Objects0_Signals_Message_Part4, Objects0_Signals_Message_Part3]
BO_ 820 Objects0_Signals_Message_Part4: 6 Vector__XXX
 SG_ Object0_Relevancy_RMC : 44|1@1+ (1,0) [0|0] "boot" Vector__XXX
 SG_ Object0_Relevancy_reserved : 45|1@1+ (1,0) [0|0] "bool" Vector__XXX
 SG_ Object0_Relevancy_LMC : 43|1@1+ (1,0) [0|0] "bool" Vector__XXX
 SG_ Object0_Relevancy_2nd_CIPV : 42|1@1+ (1,0) [0|0] "bool" Vector__XXX
 SG_ Objects_Phi_Line_Right_Obj0 : 11|9@1+ (0.0010246551382,-0.2617993878) [-0.2617993878|0.2617993878] "rad" Vector__XXX
 SG_ Objects_PhiLineRightValid_Obj0 : 10|1@1+ (1,0) [0|1] "bool" Vector__XXX
 SG_ Objects_Object_Age_Obj0 : 20|11@1+ (1,0) [0|2047] "frames" Vector__XXX
 SG_ Objects_Phi_Line_Left_Obj0 : 31|9@1+ (0.0010246551382,-0.2617993878) [-0.2617993878|0.2617993878] "rad" Vector__XXX
 SG_ Objects_Phi_Line_Left_Valid_Obj0 : 9|1@1+ (1,0) [0|1] "bool" Vector__XXX
 SG_ Objects_Lateral_Velocity_Obj0 : 0|9@1+ (0.05,-12.8) [-12.8|12.75] "m/s" Vector__XXX
 SG_ Objects_ObstacleReplaced_Obj0 : 41|1@1+ (1,0) [0|1] "bool" Vector__XXX
 SG_ Objects_CIPVFlag_Obj0 : 40|1@1+ (1,0) [0|1] "bool" Vector__XXX

BO_ 819 Objects0_Signals_Message_Part3: 5 Vector__XXX
 SG_ Objects_FOE_Y_Obj0 : 30|10@1+ (2,-1023) [-1023|1023] "pixels" Vector__XXX
 SG_ Objects_FOE_X_Obj0 : 20|10@1+ (2,-1023) [-1023|1023] "pixels" Vector__XXX
 SG_ Objects_Right_Obj0 : 10|10@1+ (2,-1023) [-1023|1023] "pixels" Vector__XXX
 SG_ Objects_Left_Obj0 : 0|10@1+ (2,-1023) [-1023|1023] "pixels" Vector__XXX

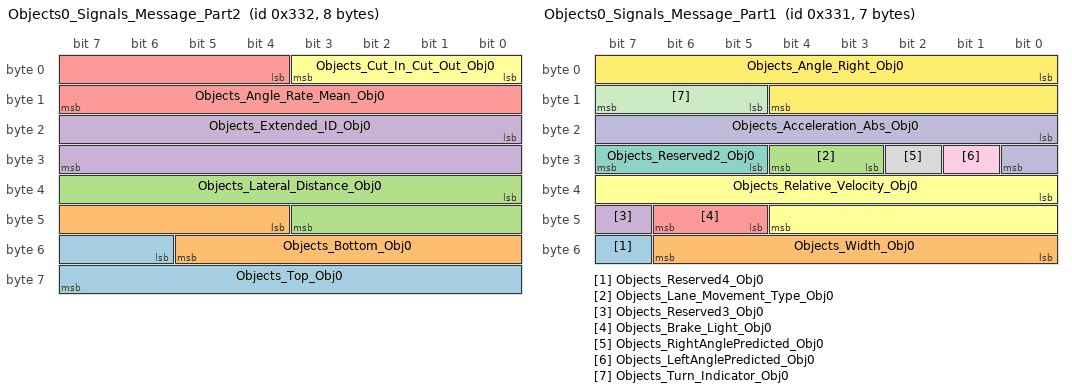
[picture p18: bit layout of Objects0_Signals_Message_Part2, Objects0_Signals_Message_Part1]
BO_ 818 Objects0_Signals_Message_Part2: 8 Vector__XXX
 SG_ Objects_Top_Obj0 : 54|10@1+ (2,-1023) [-1023|1023] "pixels" Vector__XXX
 SG_ Objects_Bottom_Obj0 : 44|10@1+ (2,-1023) [-1023|1023] "pixels" Vector__XXX
 SG_ Objects_Lateral_Distance_Obj0 : 32|12@1+ (0.05,-102.4) [-102.4|102.35] "m" Vector__XXX
 SG_ Objects_Extended_ID_Obj0 : 16|16@1+ (1,0) [0|65535] "counter" Vector__XXX
 SG_ Objects_Angle_Rate_Mean_Obj0 : 4|12@1+ (0.002,-2.234) [-2.234|2.2318] "rad/s" Vector__XXX
 SG_ Objects_Cut_In_Cut_Out_Obj0 : 0|4@1+ (1,0) [0|8] "ENUM" Vector__XXX

BO_ 817 Objects0_Signals_Message_Part1: 7 Vector__XXX
 SG_ Objects_Reserved4_Obj0 : 55|1@1+ (1,0) [0|0] "NA" Vector__XXX
 SG_ Objects_Width_Obj0 : 48|7@1+ (0.05,0) [0|6.35] "m" Vector__XXX
 SG_ Objects_Lane_Movement_Type_Obj0 : 27|2@1+ (1,0) [0|2] "ENUM" Vector__XXX
 SG_ Objects_Reserved3_Obj0 : 47|1@1+ (1,0) [0|0] "NA" Vector__XXX
 SG_ Objects_Brake_Light_Obj0 : 45|2@1+ (1,0) [0|2] "ENUM" Vector__XXX
 SG_ Objects_Relative_Velocity_Obj0 : 32|13@1+ (0.05,-128) [-128|128] "m/s" Vector__XXX
 SG_ Objects_Reserved2_Obj0 : 29|3@1+ (1,0) [0|0] "NA" Vector__XXX
 SG_ Objects_RightAnglePredicted_Obj0 : 26|1@1+ (1,0) [0|1] "bool" Vector__XXX
 SG_ Objects_LeftAnglePredicted_Obj0 : 25|1@1+ (1,0) [0|1] "bool" Vector__XXX
 SG_ Objects_Acceleration_Abs_Obj0 : 16|9@1+ (0.05,-12.8) [-12.8|12.75] "m/s2" Vector__XXX
 SG_ Objects_Turn_Indicator_Obj0 : 13|3@1+ (1,0) [0|4] "ENUM" Vector__XXX
 SG_ Objects_Angle_Right_Obj0 : 0|13@1+ (0.0002,-0.8192) [-0.8192|0.819] "rad" Vector__XXX

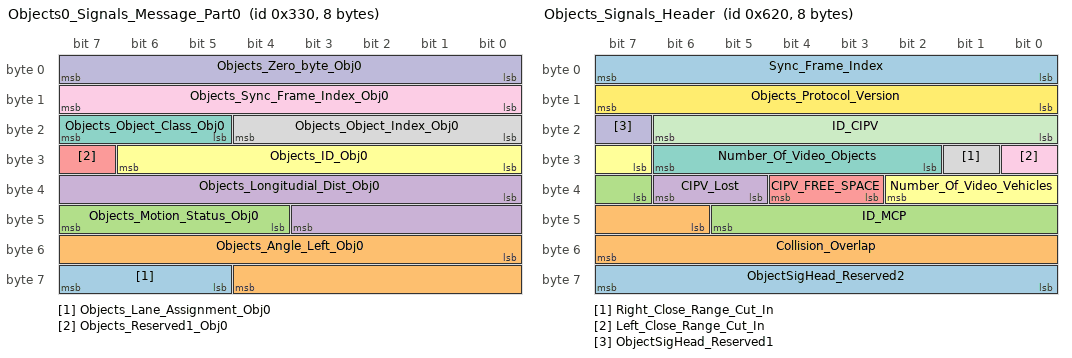
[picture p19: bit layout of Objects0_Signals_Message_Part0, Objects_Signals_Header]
BO_ 816 Objects0_Signals_Message_Part0: 8 Vector__XXX
 SG_ Objects_Lane_Assignment_Obj0 : 61|3@1+ (1,0) [0|5] "ENUM" Vector__XXX
 SG_ Objects_Angle_Left_Obj0 : 48|13@1+ (0.0002,-0.8192) [-0.8192|0.819] "rad" Vector__XXX
 SG_ Objects_Motion_Status_Obj0 : 44|4@1+ (1,0) [0|8] "ENUM" Vector__XXX
 SG_ Objects_Longitudial_Dist_Obj0 : 32|12@1+ (0.05,0) [0|204.75] "m" Vector__XXX
 SG_ Objects_Reserved1_Obj0 : 31|1@1+ (1,0) [0|0] "NA" Vector__XXX
 SG_ Objects_ID_Obj0 : 24|7@1+ (1,0) [1|63] "counter" Vector__XXX
 SG_ Objects_Object_Class_Obj0 : 21|3@1+ (1,0) [0|6] "ENUM" Vector__XXX
 SG_ Objects_Object_Index_Obj0 : 16|5@1+ (1,0) [0|19] "counter" Vector__XXX
 SG_ Objects_Sync_Frame_Index_Obj0 : 8|8@1+ (1,0) [0|255] "counter" Vector__XXX
 SG_ Objects_Zero_byte_Obj0 : 0|8@1+ (1,0) [0|0] "NA" Vector__XXX

BO_ 1568 Objects_Signals_Header: 8 Vector__XXX
 SG_ ObjectSigHead_Reserved2 : 56|8@1+ (1,0) [0|0] "NA" Vector__XXX
 SG_ Collision_Overlap : 46|10@1+ (0.01,0) [0|10.23] "meters" Vector__XXX
 SG_ ID_MCP : 39|7@1+ (1,0) [0|63] "counter" Vector__XXX
 SG_ CIPV_Lost : 37|2@1+ (1,0) [0|2] "ENUM" Vector__XXX
 SG_ CIPV_FREE_SPACE : 35|2@1+ (1,0) [0|3] "ENUM" Vector__XXX
 SG_ Number_Of_Video_Vehicles : 31|4@1+ (1,0) [0|10] "counter" Vector__XXX
 SG_ Number_Of_Video_Objects : 26|5@1+ (1,0) [0|20] "counter" Vector__XXX
 SG_ Right_Close_Range_Cut_In : 25|1@1+ (1,0) [0|1] "ENUM" Vector__XXX
 SG_ Left_Close_Range_Cut_In : 24|1@1+ (1,0) [0|1] "ENUM" Vector__XXX
 SG_ ObjectSigHead_Reserved1 : 23|1@1+ (1,0) [0|0] "NA" Vector__XXX
 SG_ ID_CIPV : 16|7@1+ (1,0) [0|63] "counter" Vector__XXX
 SG_ Objects_Protocol_Version : 8|8@1+ (1,0) [0|255] "counter" Vector__XXX
 SG_ Sync_Frame_Index : 0|8@1+ (1,0) [0|255] "counter" Vector__XXX

CM_ SG_ 1627 Lane3_Lane_Mark_Color "Color of lane mark";
CM_ SG_ 1627 Lane3_C3_Lane_Curvature_Driv "Sign according to curvature Lane_Curvature_Rate can be calculated from it";
CM_ SG_ 1626 Lane3_C2_Lane_Curvature "15m minimal radius, positive if curved to right Lane_Curvature  can be calculated from it ";
CM_ SG_ 1626 Lane3_Lane_View_Range_End "View Range ends at this distance";
CM_ SG_ 1626 Lane3_C1_Heading_Angle "positive to the right Lane Heading can be calculated from it";
CM_ SG_ 1626 Lane3_C0_Lane_Position "Positive to the right. Note this is C0 Coefficient Values are relative to the center of vehicle, according to the leftWheel & rightWheel calibration parmeters.  Lane_Position at camera point";
CM_ SG_ 1625 Lane3_Lane_View_Range_Start "Lane View Range starts at this distance";
CM_ SG_ 1625 Lane3_Lane_Mark_Width "Lnae mark width, accurcy is of 5 cm";
CM_ SG_ 1625 Lane3_Lane_Mark_Quality "Quality of lane marking";
CM_ SG_ 1625 Lane3_Lane_Mark_Type "Type of lane marking";
CM_ SG_ 1625 Lane3_Lane_Location_Type "Location of the lane";
CM_ SG_ 1625 Lane3_Lane_Index "We report upto 4 lanes";
CM_ SG_ 1625 Lane3_Sync_Frame_Index "synchronizes between the messages in the same frame";
CM_ SG_ 882 Objects_Top_Obj4 "coordinate position in image (relative to FOE coordinate in image) Assumed image size (and coordinate resolution) -  240X320 pixels (level 0)";
CM_ SG_ 882 Objects_Bottom_Obj4 "coordinate position in image (relative to FOE coordinate in image) Assumed image size (and coordinate resolution) -  240X320 pixels (level 0)";
CM_ SG_ 882 Objects_Lateral_Distance_Obj4 "positive to the right! In protocol called TRW_Objects aligned to refPoint_Y. The code subtracts the refPoint_Y from the lateral distance. If the camera islocated to the left of the refPoint_Y the value is poisitive.   ";
CM_ SG_ 882 Objects_Extended_ID_Obj4 "Raw ME ID for objects";
CM_ SG_ 882 Objects_Angle_Rate_Mean_Obj4 "proportional to speed of object mid-point in pixel coordinates in left-right direction, positive for motion to the right!";
CM_ SG_ 882 Objects_Cut_In_Cut_Out_Obj4 "Inferences can be drawn from the Cut_In_Cut_Out enum regarding Lane_Assignment and Lane_Movement_Type eg 0x1 ?Host Cut In Left -Lane_Assignment = Next Lane right   -Lane_Movement_Type = Moving Left  For full details see Mobileye comment in UART excel doc";
CM_ SG_ 866 Objects_Top_Obj3 "coordinate position in image (relative to FOE coordinate in image) Assumed image size (and coordinate resolution) -  240X320 pixels (level 0)";
CM_ SG_ 866 Objects_Bottom_Obj3 "coordinate position in image (relative to FOE coordinate in image) Assumed image size (and coordinate resolution) -  240X320 pixels (level 0)";
CM_ SG_ 866 Objects_Lateral_Distance_Obj3 "positive to the right! In protocol called TRW_Objects aligned to refPoint_Y. The code subtracts the refPoint_Y from the lateral distance. If the camera islocated to the left of the refPoint_Y the value is poisitive.   ";
CM_ SG_ 866 Objects_Extended_ID_Obj3 "Raw ME ID for objects";
CM_ SG_ 866 Objects_Angle_Rate_Mean_Obj3 "proportional to speed of object mid-point in pixel coordinates in left-right direction, positive for motion to the right!";
CM_ SG_ 866 Objects_Cut_In_Cut_Out_Obj3 "Inferences can be drawn from the Cut_In_Cut_Out enum regarding Lane_Assignment and Lane_Movement_Type eg 0x1 ?Host Cut In Left -Lane_Assignment = Next Lane right   -Lane_Movement_Type = Moving Left  For full details see Mobileye comment in UART excel doc";
CM_ SG_ 850 Objects_Top_Obj2 "coordinate position in image (relative to FOE coordinate in image) Assumed image size (and coordinate resolution) -  240X320 pixels (level 0)";
CM_ SG_ 850 Objects_Bottom_Obj2 "coordinate position in image (relative to FOE coordinate in image) Assumed image size (and coordinate resolution) -  240X320 pixels (level 0)";
CM_ SG_ 850 Objects_Lateral_Distance_Obj2 "positive to the right! In protocol called TRW_Objects aligned to refPoint_Y. The code subtracts the refPoint_Y from the lateral distance. If the camera islocated to the left of the refPoint_Y the value is poisitive.   ";
CM_ SG_ 850 Objects_Extended_ID_Obj2 "Raw ME ID for objects";
CM_ SG_ 850 Objects_Angle_Rate_Mean_Obj2 "proportional to speed of object mid-point in pixel coordinates in left-right direction, positive for motion to the right!";
CM_ SG_ 850 Objects_Cut_In_Cut_Out_Obj2 "Inferences can be drawn from the Cut_In_Cut_Out enum regarding Lane_Assignment and Lane_Movement_Type eg 0x1 ?Host Cut In Left -Lane_Assignment = Next Lane right   -Lane_Movement_Type = Moving Left  For full details see Mobileye comment in UART excel doc";
CM_ SG_ 834 Objects_Top_Obj1 "coordinate position in image (relative to FOE coordinate in image) Assumed image size (and coordinate resolution) -  240X320 pixels (level 0)";
CM_ SG_ 834 Objects_Bottom_Obj1 "coordinate position in image (relative to FOE coordinate in image) Assumed image size (and coordinate resolution) -  240X320 pixels (level 0)";
CM_ SG_ 834 Objects_Lateral_Distance_Obj1 "positive to the right! In protocol called TRW_Objects aligned to refPoint_Y. The code subtracts the refPoint_Y from the lateral distance. If the camera islocated to the left of the refPoint_Y the value is poisitive.   ";
CM_ SG_ 834 Objects_Extended_ID_Obj1 "Raw ME ID for objects";
CM_ SG_ 834 Objects_Angle_Rate_Mean_Obj1 "proportional to speed of object mid-point in pixel coordinates in left-right direction, positive for motion to the right!";
CM_ SG_ 834 Objects_Cut_In_Cut_Out_Obj1 "Inferences can be drawn from the Cut_In_Cut_Out enum regarding Lane_Assignment and Lane_Movement_Type eg 0x1 ?Host Cut In Left -Lane_Assignment = Next Lane right   -Lane_Movement_Type = Moving Left  For full details see Mobileye comment in UART excel doc";
CM_ SG_ 884 Objects_Phi_Line_Right_Obj4 "angle between left object edge and right host lane in radians (if over 15 degrees, the signal is transmitted at the max value of 15 degrees (0.261799387799149 radians) and the Valid flag will be showing invalid";
CM_ SG_ 884 Objects_PhiLineRightValid_Obj4 "Either we do not have an angle or the angle is above 15 degrees (or below -15 degrees)";
CM_ SG_ 884 Objects_Object_Age_Obj4 "A counter that indicates how many frames the object has been active for. When an object is first detected, this signal shall be initialised to 0 and incremented each succesive frame.";
CM_ SG_ 884 Objects_Phi_Line_Left_Obj4 "angle between right object edge and left host lane in radians (if over 15 degrees, the signal is transmitted at the max value of 15 degrees (0.261799387799149 radians) and the Valid flag will be showing invalid";
CM_ SG_ 884 Objects_Phi_Line_Left_Valid_Obj4 "Either we do not have an angle or the angle is above 15 degrees (or below -15 degrees)";
CM_ SG_ 884 Objects_Lateral_Velocity_Obj4 "positive to the right! ";
CM_ SG_ 868 Objects_Phi_Line_Right_Obj3 "angle between left object edge and right host lane in radians (if over 15 degrees, the signal is transmitted at the max value of 15 degrees (0.261799387799149 radians) and the Valid flag will be showing invalid";
CM_ SG_ 868 Objects_PhiLineRightValid_Obj3 "Either we do not have an angle or the angle is above 15 degrees (or below -15 degrees)";
CM_ SG_ 868 Objects_Object_Age_Obj3 "A counter that indicates how many frames the object has been active for. When an object is first detected, this signal shall be initialised to 0 and incremented each succesive frame.";
CM_ SG_ 868 Objects_Phi_Line_Left_Obj3 "angle between right object edge and left host lane in radians (if over 15 degrees, the signal is transmitted at the max value of 15 degrees (0.261799387799149 radians) and the Valid flag will be showing invalid";
CM_ SG_ 868 Objects_Phi_Line_Left_Valid_Obj3 "Either we do not have an angle or the angle is above 15 degrees (or below -15 degrees)";
CM_ SG_ 868 Objects_Lateral_Velocity_Obj3 "positive to the right! ";
CM_ SG_ 852 Objects_Phi_Line_Right_Obj2 "angle between left object edge and right host lane in radians (if over 15 degrees, the signal is transmitted at the max value of 15 degrees (0.261799387799149 radians) and the Valid flag will be showing invalid";
CM_ SG_ 852 Objects_PhiLineRightValid_Obj2 "Either we do not have an angle or the angle is above 15 degrees (or below -15 degrees)";
CM_ SG_ 852 Objects_Object_Age_Obj2 "A counter that indicates how many frames the object has been active for. When an object is first detected, this signal shall be initialised to 0 and incremented each succesive frame.";
CM_ SG_ 852 Objects_Phi_Line_Left_Obj2 "angle between right object edge and left host lane in radians (if over 15 degrees, the signal is transmitted at the max value of 15 degrees (0.261799387799149 radians) and the Valid flag will be showing invalid";
CM_ SG_ 852 Objects_Phi_Line_Left_Valid_Obj2 "Either we do not have an angle or the angle is above 15 degrees (or below -15 degrees)";
CM_ SG_ 852 Objects_Lateral_Velocity_Obj2 "positive to the right! ";
CM_ SG_ 836 Objects_Phi_Line_Right_Obj1 "angle between left object edge and right host lane in radians (if over 15 degrees, the signal is transmitted at the max value of 15 degrees (0.261799387799149 radians) and the Valid flag will be showing invalid";
CM_ SG_ 836 Objects_PhiLineRightValid_Obj1 "Either we do not have an angle or the angle is above 15 degrees (or below -15 degrees)";
CM_ SG_ 836 Objects_Object_Age_Obj1 "A counter that indicates how many frames the object has been active for. When an object is first detected, this signal shall be initialised to 0 and incremented each succesive frame.";
CM_ SG_ 836 Objects_Phi_Line_Left_Obj1 "angle between right object edge and left host lane in radians (if over 15 degrees, the signal is transmitted at the max value of 15 degrees (0.261799387799149 radians) and the Valid flag will be showing invalid";
CM_ SG_ 836 Objects_PhiLineLeftValid_Obj1 "Either we do not have an angle or the angle is above 15 degrees (or below -15 degrees)";
CM_ SG_ 836 Objects_Lateral_Velocity_Obj1 "positive to the right! ";
CM_ SG_ 883 Objects_FOE_Y_Obj4 "Level 0";
CM_ SG_ 883 Objects_FOE_X_Obj4 "Level 0";
CM_ SG_ 883 Objects_Right_Obj4 "coordinate position in image (relative to FOE coordinate in image) Assumed image size (and coordinate resolution) -  240X320 pixels (level 0)";
CM_ SG_ 883 Objects_Left_Obj4 "coordinate position in image (relative to FOE coordinate in image) Assumed image size (and coordinate resolution) -  240X320 pixels (level 0)";
CM_ SG_ 867 Objects_FOE_Y_Obj3 "Level 0";
CM_ SG_ 867 Objects_FOE_X_Obj3 "Level 0";
CM_ SG_ 867 Objects_Right_Obj3 "coordinate position in image (relative to FOE coordinate in image) Assumed image size (and coordinate resolution) -  240X320 pixels (level 0)";
CM_ SG_ 867 Objects_Left_Obj3 "coordinate position in image (relative to FOE coordinate in image) Assumed image size (and coordinate resolution) -  240X320 pixels (level 0)";
CM_ SG_ 851 Objects_FOE_Y_Obj2 "Level 0";
CM_ SG_ 851 Objects_FOE_X_Obj2 "Level 0";
CM_ SG_ 851 Objects_Right_Obj2 "coordinate position in image (relative to FOE coordinate in image) Assumed image size (and coordinate resolution) -  240X320 pixels (level 0)";
CM_ SG_ 851 Objects_Left_Obj2 "coordinate position in image (relative to FOE coordinate in image) Assumed image size (and coordinate resolution) -  240X320 pixels (level 0)";
CM_ SG_ 835 Objects_FOE_Y_Obj1 "Level 0";
CM_ SG_ 835 Objects_FOE_X_Obj1 "Level 0";
CM_ SG_ 835 Objects_Right_Obj1 "coordinate position in image (relative to FOE coordinate in image) Assumed image size (and coordinate resolution) -  240X320 pixels (level 0)";
CM_ SG_ 835 Objects_Left_Obj1 "coordinate position in image (relative to FOE coordinate in image) Assumed image size (and coordinate resolution) -  240X320 pixels (level 0)";
CM_ SG_ 881 Objects_Width_Obj4 "Object width";
CM_ SG_ 881 Objects_Lane_Movement_Type_Obj4 "the movement of a vehicle";
CM_ SG_ 881 Objects_Brake_Light_Obj4 "This signal will only be valid when the object is the CIPV";
CM_ SG_ 881 Objects_Relative_Velocity_Obj4 "positive for receding, negative for closing in";
CM_ SG_ 881 Objects_RightAnglePredicted_Obj4 "Angle Value predicted using previously determined width when right edge of vhilce is outside of the image";
CM_ SG_ 881 Objects_LeftAnglePredicted_Obj4 "Angle Value predicted using previously determined width when left edge of vhilce is outside of the image";
CM_ SG_ 881 Objects_Acceleration_Abs_Obj4 "absolute acceleration, positive for moving away from the host";
CM_ SG_ 881 Objects_Turn_Indicator_Obj4 "This signal will only be valid when the object is the CIPV";
CM_ SG_ 881 Objects_Angle_Right_Obj4 "in camera coords, this is directly proportional to the pixel values, so no small angle approximation, positive to the right!";
CM_ SG_ 865 Objects_Width_Obj3 "Object width";
CM_ SG_ 865 Objects_Lane_Movement_Type_Obj3 "the movement of a vehicle";
CM_ SG_ 865 Objects_Brake_Light_Obj3 "This signal will only be valid when the object is the CIPV";
CM_ SG_ 865 Objects_Relative_Velocity_Obj3 "positive for receding, negative for closing in";
CM_ SG_ 865 Objects_RightAnglePredicted_Obj3 "Angle Value predicted using previously determined width when right edge of vhilce is outside of the image";
CM_ SG_ 865 Objects_LeftAnglePredicted_Obj3 "Angle Value predicted using previously determined width when left edge of vhilce is outside of the image";
CM_ SG_ 865 Objects_Acceleration_Abs_Obj3 "absolute acceleration, positive for moving away from the host";
CM_ SG_ 865 Objects_Turn_Indicator_Obj3 "This signal will only be valid when the object is the CIPV";
CM_ SG_ 865 Objects_Angle_Right_Obj3 "in camera coords, this is directly proportional to the pixel values, so no small angle approximation, positive to the right!";
CM_ SG_ 849 Objects_Width_Obj2 "Object width";
CM_ SG_ 849 Objects_Lane_Movement_Type_Obj2 "the movement of a vehicle";
CM_ SG_ 849 Objects_Brake_Light_Obj2 "This signal will only be valid when the object is the CIPV";
CM_ SG_ 849 Objects_Relative_Velocity_Obj2 "positive for receding, negative for closing in";
CM_ SG_ 849 Objects_RightAnglePredicted_Obj2 "Angle Value predicted using previously determined width when right edge of vhilce is outside of the image";
CM_ SG_ 849 Objects_LeftAnglePredicted_Obj2 "Angle Value predicted using previously determined width when left edge of vhilce is outside of the image";
CM_ SG_ 849 Objects_Acceleration_Abs_Obj2 "absolute acceleration, positive for moving away from the host";
CM_ SG_ 849 Objects_Turn_Indicator_Obj2 "This signal will only be valid when the object is the CIPV";
CM_ SG_ 849 Objects_Angle_Right_Obj2 "in camera coords, this is directly proportional to the pixel values, so no small angle approximation, positive to the right!";
CM_ SG_ 833 Objects_Width_Obj1 "Object width";
CM_ SG_ 833 Objects_Lane_Movement_Type_Obj1 "the movement of a vehicle";
CM_ SG_ 833 Objects_Brake_Light_Obj1 "This signal will only be valid when the object is the CIPV";
CM_ SG_ 833 Objects_Relative_Velocity_Obj1 "positive for receding, negative for closing in";
CM_ SG_ 833 Objects_RightAnglePredicted_Obj1 "Angle Value predicted using previously determined width when right edge of vhilce is outside of the image";
CM_ SG_ 833 Objects_LeftAnglePredicted_Obj1 "Angle Value predicted using previously determined width when left edge of vhilce is outside of the image";
CM_ SG_ 833 Objects_Acceleration_Abs_Obj1 "absolute acceleration, positive for moving away from the host";
CM_ SG_ 833 Objects_Turn_Indicator_Obj1 "This signal will only be valid when the object is the CIPV";
CM_ SG_ 833 Objects_Angle_Right_Obj1 "in camera coords, this is directly proportional to the pixel values, so no small angle approximation, positive to the right!";
CM_ SG_ 880 Objects_Lane_Assignment_Obj4 "Which lane a vehicle belongs to";
CM_ SG_ 880 Objects_Angle_Left_Obj4 "in camera coords, this is directly proportional to the pixel values, so no small angle approximation, positive to the right!";
CM_ SG_ 880 Objects_Motion_Status_Obj4 "Defines motion status of detected vehicle";
CM_ SG_ 880 Objects_Longitudial_Dist_Obj4 "in protocol called TRW_Objects alligned to ref_point_x";
CM_ SG_ 880 Objects_ID_Obj4 "ValidObject = 1 to 63";
CM_ SG_ 880 Objects_Object_Class_Obj4 "0x6 (undecided) represents when no decision yet has been made about class - car or truck 0x0 represents unknown object";
CM_ SG_ 880 Objects_Object_Index_Obj4 "If we send 20 objects, the index will be 0 - 19";
CM_ SG_ 880 Objects_Sync_Frame_Index_Obj4 "synchronizes between the messages in the same frame";
CM_ SG_ 864 Objects_Lane_Assignment_Obj3 "Which lane a vehicle belongs to";
CM_ SG_ 864 Objects_Angle_Left_Obj3 "in camera coords, this is directly proportional to the pixel values, so no small angle approximation, positive to the right!";
CM_ SG_ 864 Objects_Motion_Status_Obj3 "Defines motion status of detected vehicle";
CM_ SG_ 864 Objects_Longitudial_Dist_Obj3 "in protocol called TRW_Objects alligned to ref_point_x";
CM_ SG_ 864 Objects_ID_Obj3 "ValidObject = 1 to 63";
CM_ SG_ 864 Objects_Object_Class_Obj3 "0x6 (undecided) represents when no decision yet has been made about class - car or truck 0x0 represents unknown object";
CM_ SG_ 864 Objects_Object_Index_Obj3 "If we send 20 objects, the index will be 0 - 19";
CM_ SG_ 864 Objects_Sync_Frame_Index_Obj3 "synchronizes between the messages in the same frame";
CM_ SG_ 848 Objects_Lane_Assignment_Obj2 "Which lane a vehicle belongs to";
CM_ SG_ 848 Objects_Angle_Left_Obj2 "in camera coords, this is directly proportional to the pixel values, so no small angle approximation, positive to the right!";
CM_ SG_ 848 Objects_Motion_Status_Obj2 "Defines motion status of detected vehicle";
CM_ SG_ 848 Objects_Longitudial_Dist_Obj2 "in protocol called TRW_Objects alligned to ref_point_x";
CM_ SG_ 848 Objects_ID_Obj2 "ValidObject = 1 to 63";
CM_ SG_ 848 Objects_Object_Class_Obj2 "0x6 (undecided) represents when no decision yet has been made about class - car or truck 0x0 represents unknown object";
CM_ SG_ 848 Objects_Object_Index_Obj2 "If we send 20 objects, the index will be 0 - 19";
CM_ SG_ 848 Objects_Sync_Frame_Index_Obj2 "synchronizes between the messages in the same frame";
CM_ SG_ 832 Objects_Lane_Assignment_Obj1 "Which lane a vehicle belongs to";
CM_ SG_ 832 Objects_Angle_Left_Obj1 "in camera coords, this is directly proportional to the pixel values, so no small angle approximation, positive to the right!";
CM_ SG_ 832 Objects_Motion_Status_Obj1 "Defines motion status of detected vehicle";
CM_ SG_ 832 Objects_Longitudial_Dist_Obj1 "in protocol called TRW_Objects alligned to ref_point_x";
CM_ SG_ 832 Objects_ID_Obj1 "ValidObject = 1 to 63";
CM_ SG_ 832 Objects_Object_Class_Obj1 "0x6 (undecided) represents when no decision yet has been made about class - car or truck 0x0 represents unknown object";
CM_ SG_ 832 Objects_Object_Index_Obj1 "If we send 20 objects, the index will be 0 - 19";
CM_ SG_ 832 Objects_Sync_Frame_Index_Obj1 "synchronizes between the messages in the same frame";
CM_ SG_ 1536 CS_VehicleSpeed "speed";
CM_ SG_ 1536 CS_VehicleYaw "Positive on right turn";
CM_ SG_ 1536 CS_SteeringWheelAngle "Angle to the right is positive";
CM_ SG_ 820 Object0_Relevancy_RMC "Relevancy_right_most_critical";
CM_ SG_ 820 Object0_Relevancy_LMC "Relevancy_left_most_critical_obj";
CM_ SG_ 820 Objects_Phi_Line_Right_Obj0 "angle between left object edge and right host lane in radians (if over 15 degrees, the signal is transmitted at the max value of 15 degrees (0.261799387799149 radians) and the Valid flag will be showing invalid";
CM_ SG_ 820 Objects_PhiLineRightValid_Obj0 "Either we do not have an angle or the angle is above 15 degrees (or below -15 degrees)";
CM_ SG_ 820 Objects_Object_Age_Obj0 "A counter that indicates how many frames the object has been active for. When an object is first detected, this signal shall be initialised to 0 and incremented each succesive frame.";
CM_ SG_ 820 Objects_Phi_Line_Left_Obj0 "angle between right object edge and left host lane in radians (if over 15 degrees, the signal is transmitted at the max value of 15 degrees (0.261799387799149 radians) and the Valid flag will be showing invalid";
CM_ SG_ 820 Objects_Phi_Line_Left_Valid_Obj0 "Either we do not have an angle or the angle is above 15 degrees (or below -15 degrees)";
CM_ SG_ 820 Objects_Lateral_Velocity_Obj0 "positive to the right! ";
CM_ SG_ 819 Objects_FOE_Y_Obj0 "Level 0";
CM_ SG_ 819 Objects_FOE_X_Obj0 "Level 0";
CM_ SG_ 819 Objects_Right_Obj0 "coordinate position in image (relative to FOE coordinate in image) Assumed image size (and coordinate resolution) -  240X320 pixels (level 0)";
CM_ SG_ 819 Objects_Left_Obj0 "coordinate position in image (relative to FOE coordinate in image) Assumed image size (and coordinate resolution) -  240X320 pixels (level 0)";
CM_ SG_ 818 Objects_Top_Obj0 "coordinate position in image (relative to FOE coordinate in image) Assumed image size (and coordinate resolution) -  240X320 pixels (level 0)";
CM_ SG_ 818 Objects_Bottom_Obj0 "coordinate position in image (relative to FOE coordinate in image) Assumed image size (and coordinate resolution) -  240X320 pixels (level 0)";
CM_ SG_ 818 Objects_Lateral_Distance_Obj0 "positive to the right! In protocol called TRW_Objects aligned to refPoint_Y. The code subtracts the refPoint_Y from the lateral distance. If the camera islocated to the left of the refPoint_Y the value is poisitive.   ";
CM_ SG_ 818 Objects_Extended_ID_Obj0 "Raw ME ID for objects";
CM_ SG_ 818 Objects_Angle_Rate_Mean_Obj0 "proportional to speed of object mid-point in pixel coordinates in left-right direction, positive for motion to the right!";
CM_ SG_ 818 Objects_Cut_In_Cut_Out_Obj0 "Inferences can be drawn from the Cut_In_Cut_Out enum regarding Lane_Assignment and Lane_Movement_Type eg 0x1 ?Host Cut In Left -Lane_Assignment = Next Lane right   -Lane_Movement_Type = Moving Left  For full details see Mobileye comment in UART excel doc";
CM_ SG_ 817 Objects_Width_Obj0 "Object width";
CM_ SG_ 817 Objects_Lane_Movement_Type_Obj0 "the movement of a vehicle";
CM_ SG_ 817 Objects_Brake_Light_Obj0 "This signal will only be valid when the object is the CIPV";
CM_ SG_ 817 Objects_Relative_Velocity_Obj0 "positive for receding, negative for closing in";
CM_ SG_ 817 Objects_RightAnglePredicted_Obj0 "Angle Value predicted using previously determined width when right edge of vhilce is outside of the image";
CM_ SG_ 817 Objects_LeftAnglePredicted_Obj0 "Angle Value predicted using previously determined width when left edge of vhilce is outside of the image";
CM_ SG_ 817 Objects_Acceleration_Abs_Obj0 "absolute acceleration, positive for moving away from the host";
CM_ SG_ 817 Objects_Turn_Indicator_Obj0 "This signal will only be valid when the object is the CIPV";
CM_ SG_ 817 Objects_Angle_Right_Obj0 "in camera coords, this is directly proportional to the pixel values, so no small angle approximation, positive to the right!";
CM_ SG_ 816 Objects_Lane_Assignment_Obj0 "Which lane a vehicle belongs to";
CM_ SG_ 816 Objects_Angle_Left_Obj0 "in camera coords, this is directly proportional to the pixel values, so no small angle approximation, positive to the right!";
CM_ SG_ 816 Objects_Motion_Status_Obj0 "Defines motion status of detected vehicle";
CM_ SG_ 816 Objects_Longitudial_Dist_Obj0 "in protocol called TRW_Objects alligned to ref_point_x";
CM_ SG_ 816 Objects_ID_Obj0 "ValidObject = 1 to 63";
CM_ SG_ 816 Objects_Object_Class_Obj0 "0x6 (undecided) represents when no decision yet has been made about class - car or truck 0x0 represents unknown object";
CM_ SG_ 816 Objects_Object_Index_Obj0 "If we send 20 objects, the index will be 0 - 19";
CM_ SG_ 816 Objects_Sync_Frame_Index_Obj0 "synchronizes between the messages in the same frame";
CM_ SG_ 1568 Collision_Overlap "Collision Overlap";
CM_ SG_ 1568 ID_MCP "The Most Critical Pedestrian i.e. the pedestrian that could result in a TTC alert (equivalent to the CIPV).";
CM_ SG_ 1568 CIPV_Lost "State of the CIPV in terms of its loss";
CM_ SG_ 1568 CIPV_FREE_SPACE "Detects all big enough obj which enter the CIPV Free Space area, which begins at the ego veh and ends at the CIPV veh, and can be assumed at a max dist of 15m. The width of the CIPV Free Space is a configurable. Only active at EGO speed <15km/h. ";
CM_ SG_ 1568 Number_Of_Video_Vehicles "Number of Peds = Objects - Vehicles";
CM_ SG_ 1568 Number_Of_Video_Objects "Number of objects detected";
CM_ SG_ 1568 Right_Close_Range_Cut_In "Check enum values";
CM_ SG_ 1568 Left_Close_Range_Cut_In "Check enum values";
CM_ SG_ 1568 ID_CIPV "Denotes the ID of the object";
CM_ SG_ 1568 Objects_Protocol_Version "Used to define the version number of this protocol";
CM_ SG_ 1568 Sync_Frame_Index "synchronizes between the messages in the same frame";
BA_DEF_ BO_  "NmMessage" ENUM  "Not","Yes";
BA_DEF_ BO_  "DiagResponse" ENUM  "Not","Yes";
BA_DEF_ BO_  "DiagRequest" ENUM  "Not","Yes";
BA_DEF_ SG_  "GenSigEnvVarType" ENUM  "int","float","undef";
BA_DEF_ SG_  "GenSigStartValue" FLOAT 0 1215752192;
BA_DEF_ BO_  "GenMsgILSupport" ENUM  "No","Yes";
BA_DEF_ SG_  "GenSigSendType" ENUM  "Cyclic","OnWrite","OnWriteWithRepetition","OnChange","OnChangeWithRepetition","IfActive","IfActiveWithRepetition","NoSigSendType";
BA_DEF_ BO_  "GenMsgCycleTime" INT 0 0;
BA_DEF_ BO_  "GenMsgSendType" ENUM  "Cyclic","not_used","not_used","not_used","not_used","Cyclic","not_used","IfActive","NoMsgSendType","On Event";
BA_DEF_DEF_  "NmMessage" "Not";
BA_DEF_DEF_  "DiagResponse" "Not";
BA_DEF_DEF_  "DiagRequest" "Not";
BA_DEF_DEF_  "GenSigEnvVarType" "undef";
BA_DEF_DEF_  "GenSigStartValue" 0;
BA_DEF_DEF_  "GenMsgILSupport" "No";
BA_DEF_DEF_  "GenSigSendType" "Cyclic";
BA_DEF_DEF_  "GenMsgCycleTime" 0;
BA_DEF_DEF_  "GenMsgSendType" "NoMsgSendType";
BA_ "GenMsgILSupport" BO_ 1624 1;
BA_ "GenMsgCycleTime" BO_ 1624 20;
BA_ "GenMsgSendType" BO_ 1624 0;
BA_ "GenMsgILSupport" BO_ 1623 1;
BA_ "GenMsgCycleTime" BO_ 1623 20;
BA_ "GenMsgSendType" BO_ 1623 0;
BA_ "GenMsgILSupport" BO_ 1622 1;
BA_ "GenMsgCycleTime" BO_ 1622 20;
BA_ "GenMsgSendType" BO_ 1622 0;
BA_ "GenMsgILSupport" BO_ 1627 1;
BA_ "GenMsgCycleTime" BO_ 1627 20;
BA_ "GenMsgSendType" BO_ 1627 0;
BA_ "GenMsgILSupport" BO_ 1626 1;
BA_ "GenMsgCycleTime" BO_ 1626 20;
BA_ "GenMsgSendType" BO_ 1626 0;
BA_ "GenMsgILSupport" BO_ 1625 1;
BA_ "GenMsgCycleTime" BO_ 1625 20;
BA_ "GenMsgSendType" BO_ 1625 0;
BA_ "GenMsgSendType" BO_ 882 0;
BA_ "GenMsgCycleTime" BO_ 882 20;
BA_ "GenMsgILSupport" BO_ 882 1;
BA_ "GenMsgSendType" BO_ 866 0;
BA_ "GenMsgCycleTime" BO_ 866 20;
BA_ "GenMsgILSupport" BO_ 866 1;
BA_ "GenMsgSendType" BO_ 850 0;
BA_ "GenMsgCycleTime" BO_ 850 20;
BA_ "GenMsgILSupport" BO_ 850 1;
BA_ "GenMsgSendType" BO_ 834 0;
BA_ "GenMsgCycleTime" BO_ 834 20;
BA_ "GenMsgILSupport" BO_ 834 1;
BA_ "GenMsgSendType" BO_ 884 0;
BA_ "GenMsgCycleTime" BO_ 884 20;
BA_ "GenMsgILSupport" BO_ 884 1;
BA_ "GenMsgSendType" BO_ 868 0;
BA_ "GenMsgCycleTime" BO_ 868 20;
BA_ "GenMsgILSupport" BO_ 868 1;
BA_ "GenMsgSendType" BO_ 852 0;
BA_ "GenMsgCycleTime" BO_ 852 20;
BA_ "GenMsgILSupport" BO_ 852 1;
BA_ "GenMsgSendType" BO_ 836 0;
BA_ "GenMsgCycleTime" BO_ 836 20;
BA_ "GenMsgILSupport" BO_ 836 1;
BA_ "GenMsgSendType" BO_ 883 0;
BA_ "GenMsgCycleTime" BO_ 883 20;
BA_ "GenMsgILSupport" BO_ 883 1;
BA_ "GenMsgSendType" BO_ 867 0;
BA_ "GenMsgCycleTime" BO_ 867 20;
BA_ "GenMsgILSupport" BO_ 867 1;
BA_ "GenMsgSendType" BO_ 851 0;
BA_ "GenMsgCycleTime" BO_ 851 20;
BA_ "GenMsgILSupport" BO_ 851 1;
BA_ "GenMsgSendType" BO_ 835 0;
BA_ "GenMsgCycleTime" BO_ 835 20;
BA_ "GenMsgILSupport" BO_ 835 1;
BA_ "GenMsgSendType" BO_ 881 0;
BA_ "GenMsgCycleTime" BO_ 881 20;
BA_ "GenMsgILSupport" BO_ 881 1;
BA_ "GenMsgSendType" BO_ 865 0;
BA_ "GenMsgCycleTime" BO_ 865 20;
BA_ "GenMsgILSupport" BO_ 865 1;
BA_ "GenMsgSendType" BO_ 849 0;
BA_ "GenMsgCycleTime" BO_ 849 20;
BA_ "GenMsgILSupport" BO_ 849 1;
BA_ "GenMsgSendType" BO_ 833 0;
BA_ "GenMsgCycleTime" BO_ 833 20;
BA_ "GenMsgILSupport" BO_ 833 1;
BA_ "GenMsgSendType" BO_ 880 0;
BA_ "GenMsgCycleTime" BO_ 880 20;
BA_ "GenMsgILSupport" BO_ 880 1;
BA_ "GenMsgSendType" BO_ 864 0;
BA_ "GenMsgCycleTime" BO_ 864 20;
BA_ "GenMsgILSupport" BO_ 864 1;
BA_ "GenMsgSendType" BO_ 848 0;
BA_ "GenMsgCycleTime" BO_ 848 20;
BA_ "GenMsgILSupport" BO_ 848 1;
BA_ "GenMsgSendType" BO_ 832 0;
BA_ "GenMsgCycleTime" BO_ 832 20;
BA_ "GenMsgILSupport" BO_ 832 1;
BA_ "GenMsgILSupport" BO_ 1536 1;
BA_ "GenMsgSendType" BO_ 1536 0;
BA_ "GenMsgCycleTime" BO_ 1536 20;
BA_ "GenMsgILSupport" BO_ 1621 1;
BA_ "GenMsgCycleTime" BO_ 1621 20;
BA_ "GenMsgSendType" BO_ 1621 0;
BA_ "GenMsgILSupport" BO_ 1620 1;
BA_ "GenMsgCycleTime" BO_ 1620 20;
BA_ "GenMsgSendType" BO_ 1620 0;
BA_ "GenMsgILSupport" BO_ 1619 1;
BA_ "GenMsgCycleTime" BO_ 1619 20;
BA_ "GenMsgSendType" BO_ 1619 0;
BA_ "GenMsgILSupport" BO_ 1618 1;
BA_ "GenMsgCycleTime" BO_ 1618 20;
BA_ "GenMsgSendType" BO_ 1618 0;
BA_ "GenMsgILSupport" BO_ 1617 1;
BA_ "GenMsgCycleTime" BO_ 1617 20;
BA_ "GenMsgSendType" BO_ 1617 0;
BA_ "GenMsgILSupport" BO_ 1616 1;
BA_ "GenMsgCycleTime" BO_ 1616 20;
BA_ "GenMsgSendType" BO_ 1616 0;
BA_ "GenMsgILSupport" BO_ 820 1;
BA_ "GenMsgCycleTime" BO_ 820 20;
BA_ "GenMsgSendType" BO_ 820 0;
BA_ "GenMsgILSupport" BO_ 819 1;
BA_ "GenMsgCycleTime" BO_ 819 20;
BA_ "GenMsgSendType" BO_ 819 0;
BA_ "GenMsgILSupport" BO_ 818 1;
BA_ "GenMsgCycleTime" BO_ 818 20;
BA_ "GenMsgSendType" BO_ 818 0;
BA_ "GenMsgILSupport" BO_ 817 1;
BA_ "GenMsgCycleTime" BO_ 817 20;
BA_ "GenMsgSendType" BO_ 817 0;
BA_ "GenMsgILSupport" BO_ 816 1;
BA_ "GenMsgCycleTime" BO_ 816 20;
BA_ "GenMsgSendType" BO_ 816 0;
BA_ "GenMsgILSupport" BO_ 1568 1;
BA_ "GenMsgCycleTime" BO_ 1568 20;
BA_ "GenMsgSendType" BO_ 1568 0;
VAL_ 1624 Lane2_Lane_Mark_Color 3 "Blue" 2 "Yelow" 1 "White" 0 "Unknown" ;
VAL_ 1622 Lane2_Lane_Mark_Quality 3 "high" 2 "medium" 1 "low2" 0 "low1" ;
VAL_ 1622 Lane2_Lane_Mark_Type 3 "Next Right" 2 "Next Left" 1 "Right" 0 "Left" ;
VAL_ 1622 Lane2_Lane_Location_Type 3 "Next Right" 2 "Next Left" 1 "Right" 0 "Left" ;
VAL_ 1627 Lane3_Lane_Mark_Color 3 "Blue" 2 "Yelow" 1 "White" 0 "Unknown" ;
VAL_ 1625 Lane3_Lane_Mark_Quality 3 "high" 2 "medium" 1 "low2" 0 "low1" ;
VAL_ 1625 Lane3_Lane_Mark_Type 6 "Barrier" 5 "Bott'sDots" 4 "DoubleLane" 3 "Dashed" 2 "RoadEdge" 1 "Solid" 0 "Undecided" ;
VAL_ 1625 Lane3_Lane_Location_Type 3 "Next Right" 2 "Next Left" 1 "Right" 0 "Left" ;
VAL_ 882 Objects_Cut_In_Cut_Out_Obj4 8 "Next Cut Out Right" 7 "Next Cut Out Left" 6 "Next Cut In Right" 5 "Next Cut In Left" 4 "Host Cut Out Right" 3 "Host Cut Out Left" 2 "Host Cut In Right" 1 "Host Cut In Left" 0 "Unknown" ;
VAL_ 866 Objects_Cut_In_Cut_Out_Obj3 8 "Next Cut Out Right" 7 "Next Cut Out Left" 6 "Next Cut In Right" 5 "Next Cut In Left" 4 "Host Cut Out Right" 3 "Host Cut Out Left" 2 "Host Cut In Right" 1 "Host Cut In Left" 0 "Unknown" ;
VAL_ 850 Objects_Cut_In_Cut_Out_Obj2 8 "Next Cut Out Right" 7 "Next Cut Out Left" 6 "Next Cut In Right" 5 "Next Cut In Left" 4 "Host Cut Out Right" 3 "Host Cut Out Left" 2 "Host Cut In Right" 1 "Host Cut In Left" 0 "Unknown" ;
VAL_ 834 Objects_Cut_In_Cut_Out_Obj1 8 "Next Cut Out Right" 7 "Next Cut Out Left" 6 "Next Cut In Right" 5 "Next Cut In Left" 4 "Host Cut Out Right" 3 "Host Cut Out Left" 2 "Host Cut In Right" 1 "Host Cut In Left" 0 "Unknown" ;
VAL_ 884 Objects_PhiLineRightValid_Obj4 1 "Valid" 0 "Invalid" ;
VAL_ 884 Objects_Phi_Line_Left_Valid_Obj4 1 "Valid" 0 "Invalid" ;
VAL_ 868 Objects_PhiLineRightValid_Obj3 1 "Valid" 0 "Invalid" ;
VAL_ 868 Objects_Phi_Line_Left_Valid_Obj3 1 "Valid" 0 "Invalid" ;
VAL_ 852 Objects_PhiLineRightValid_Obj2 1 "Valid" 0 "Invalid" ;
VAL_ 852 Objects_Phi_Line_Left_Valid_Obj2 1 "Valid" 0 "Invalid" ;
VAL_ 836 Objects_PhiLineRightValid_Obj1 1 "Valid" 0 "Invalid" ;
VAL_ 836 Objects_PhiLineLeftValid_Obj1 1 "Valid" 0 "Invalid" ;
VAL_ 881 Objects_Lane_Movement_Type_Obj4 2 "Moving Right" 1 "Moving Left" 0 "Unknown" ;
VAL_ 881 Objects_Brake_Light_Obj4 2 "Off" 1 "On" 0 "Not available" ;
VAL_ 881 Objects_RightAnglePredicted_Obj4 1 "True" 0 "False" ;
VAL_ 881 Objects_LeftAnglePredicted_Obj4 1 "True" 0 "False" ;
VAL_ 865 Objects_Lane_Movement_Type_Obj3 2 "Moving Right" 1 "Moving Left" 0 "Unknown" ;
VAL_ 865 Objects_Brake_Light_Obj3 2 "Off" 1 "On" 0 "Not available" ;
VAL_ 865 Objects_RightAnglePredicted_Obj3 1 "True" 0 "False" ;
VAL_ 865 Objects_LeftAnglePredicted_Obj3 1 "True" 0 "False" ;
VAL_ 849 Objects_Lane_Movement_Type_Obj2 2 "Moving Right" 1 "Moving Left" 0 "Unknown" ;
VAL_ 849 Objects_Brake_Light_Obj2 2 "Off" 1 "On" 0 "Not available" ;
VAL_ 849 Objects_RightAnglePredicted_Obj2 1 "True" 0 "False" ;
VAL_ 849 Objects_LeftAnglePredicted_Obj2 1 "True" 0 "False" ;
VAL_ 833 Objects_Lane_Movement_Type_Obj1 2 "Moving Right" 1 "Moving Left" 0 "Unknown" ;
VAL_ 833 Objects_Brake_Light_Obj1 2 "Off" 1 "On" 0 "Not available" ;
VAL_ 833 Objects_RightAnglePredicted_Obj1 1 "True" 0 "False" ;
VAL_ 833 Objects_LeftAnglePredicted_Obj1 1 "True" 0 "False" ;
VAL_ 880 Objects_Lane_Assignment_Obj4 5 "Next next Lane right" 4 "Next next Lane left" 3 "Next Lane right" 2 "Next Lane left" 1 "Ego Lane" 0 "Not assigned" ;
VAL_ 880 Objects_Motion_Status_Obj4 8 "Moving (Oncoming )" 7 "Unknown (Oncoming )" 6 "Stopped (Oncoming )" 5 "Moving (movable)" 4 "Unknown (movable)" 3 "Stopped (movable)" 2 "Parked (never moved, back lights are off)" 1 "Standing (never moved back lights are on)" 0 "Not Defined" ;
VAL_ 880 Objects_Object_Class_Obj4 6 "Undecided" 5 "Pedestrian" 4 "Bicycle" 3 "MotorBike" 2 "Car" 1 "Truck" 0 "Unknown" ;
VAL_ 864 Objects_Lane_Assignment_Obj3 5 "Next next Lane right" 4 "Next next Lane left" 3 "Next Lane right" 2 "Next Lane left" 1 "Ego Lane" 0 "Not assigned" ;
VAL_ 864 Objects_Motion_Status_Obj3 8 "Moving (Oncoming )" 7 "Unknown (Oncoming )" 6 "Stopped (Oncoming )" 5 "Moving (movable)" 4 "Unknown (movable)" 3 "Stopped (movable)" 2 "Parked (never moved, back lights are off)" 1 "Standing (never moved back lights are on)" 0 "Not Defined" ;
VAL_ 864 Objects_Object_Class_Obj3 6 "Undecided" 5 "Pedestrian" 4 "Bicycle" 3 "MotorBike" 2 "Car" 1 "Truck" 0 "Unknown" ;
VAL_ 848 Objects_Lane_Assignment_Obj2 5 "Next next Lane right" 4 "Next next Lane left" 3 "Next Lane right" 2 "Next Lane left" 1 "Ego Lane" 0 "Not assigned" ;
VAL_ 848 Objects_Motion_Status_Obj2 8 "Moving (Oncoming )" 7 "Unknown (Oncoming )" 6 "Stopped (Oncoming )" 5 "Moving (movable)" 4 "Unknown (movable)" 3 "Stopped (movable)" 2 "Parked (never moved, back lights are off)" 1 "Standing (never moved back lights are on)" 0 "Not Defined" ;
VAL_ 848 Objects_Object_Class_Obj2 6 "Undecided" 5 "Pedestrian" 4 "Bicycle" 3 "MotorBike" 2 "Car" 1 "Truck" 0 "Unknown" ;
VAL_ 832 Objects_Lane_Assignment_Obj1 5 "Next next Lane right" 4 "Next next Lane left" 3 "Next Lane right" 2 "Next Lane left" 1 "Ego Lane" 0 "Not assigned" ;
VAL_ 832 Objects_Motion_Status_Obj1 8 "Moving (Oncoming )" 7 "Unknown (Oncoming )" 6 "Stopped (Oncoming )" 5 "Moving (movable)" 4 "Unknown (movable)" 3 "Stopped (movable)" 2 "Parked (never moved, back lights are off)" 1 "Standing (never moved back lights are on)" 0 "Not Defined" ;
VAL_ 832 Objects_Object_Class_Obj1 6 "Undecided" 5 "Pedestrian" 4 "Bicycle" 3 "MotorBike" 2 "Car" 1 "Truck" 0 "Unknown" ;
VAL_ 1621 Lane1_Lane_Mark_Color 3 "Blue" 2 "Yelow" 1 "White" 0 "Unknown" ;
VAL_ 1619 Lane1_Lane_Mark_Quality 3 "high" 2 "medium" 1 "low2" 0 "low1" ;
VAL_ 1619 Lane1_Lane_Mark_Type 3 "Next Right" 2 "Next Left" 1 "Right" 0 "Left" ;
VAL_ 1619 Lane1_Lane_Location_Type 3 "Next Right" 2 "Next Left" 1 "Right" 0 "Left" ;
VAL_ 1618 Lane0_Lane_Mark_Color 3 "Blue" 2 "Yelow" 1 "White" 0 "Unknown" ;
VAL_ 1616 Lane0_Lane_Mark_Quality 3 "high" 2 "medium" 1 "low2" 0 "low1" ;
VAL_ 1616 Lane0_Lane_Mark_Type 3 "Next Right" 2 "Next Left" 1 "Right" 0 "Left" ;
VAL_ 1616 Lane0_Lane_Location_Type 3 "Next Right" 2 "Next Left" 1 "Right" 0 "Left" ;
VAL_ 820 Objects_PhiLineRightValid_Obj0 1 "Valid" 0 "Invalid" ;
VAL_ 820 Objects_Phi_Line_Left_Valid_Obj0 1 "Valid" 0 "Invalid" ;
VAL_ 818 Objects_Cut_In_Cut_Out_Obj0 8 "Next Cut Out Right" 7 "Next Cut Out Left" 6 "Next Cut In Right" 5 "Next Cut In Left" 4 "Host Cut Out Right" 3 "Host Cut Out Left" 2 "Host Cut In Right" 1 "Host Cut In Left" 0 "Unknown" ;
VAL_ 817 Objects_Lane_Movement_Type_Obj0 2 "Moving Right" 1 "Moving Left" 0 "Unknown" ;
VAL_ 817 Objects_Brake_Light_Obj0 2 "Off" 1 "On" 0 "Not available" ;
VAL_ 817 Objects_RightAnglePredicted_Obj0 1 "True" 0 "False" ;
VAL_ 817 Objects_LeftAnglePredicted_Obj0 1 "True" 0 "False" ;
VAL_ 816 Objects_Lane_Assignment_Obj0 5 "Next next Lane right" 4 "Next next Lane left" 3 "Next Lane right" 2 "Next Lane left" 1 "Ego Lane" 0 "Not assigned" ;
VAL_ 816 Objects_Motion_Status_Obj0 8 "Moving (Oncoming )" 7 "Unknown (Oncoming )" 6 "Stopped (Oncoming )" 5 "Moving (movable)" 4 "Unknown (movable)" 3 "Stopped (movable)" 2 "Parked (never moved, back lights are off)" 1 "Standing (never moved back lights are on)" 0 "Not Defined" ;
VAL_ 816 Objects_Object_Class_Obj0 6 "Undecided" 5 "Pedestrian" 4 "Bicycle" 3 "MotorBike" 2 "Car" 1 "Truck" 0 "Unknown" ;
VAL_ 1568 CIPV_Lost 2 "LOST_TARGET_FOV_IN" 1 "LOST_TARGET_FOV_OUT" 0 "NO_LOSS" ;
VAL_ 1568 CIPV_FREE_SPACE 3 "Reserved" 2 "No statement possible" 1 "Penetration detected" 0 "No Penetration detected" ;
VAL_ 1568 Right_Close_Range_Cut_In 1 "Cut In" 0 "No Cut In" ;
VAL_ 1568 Left_Close_Range_Cut_In 1 "Cut In" 0 "No Cut In" ;
